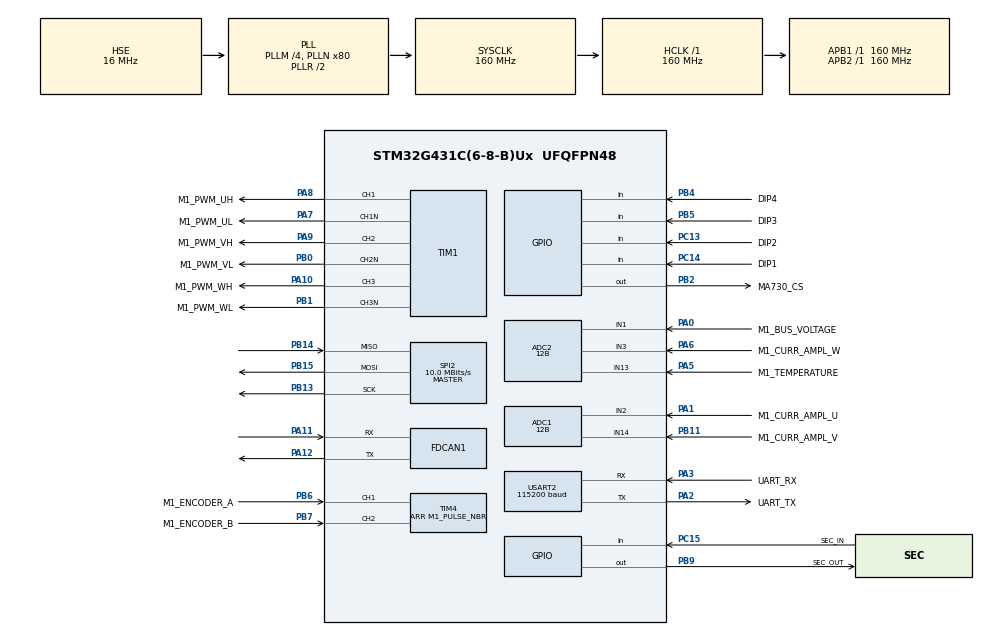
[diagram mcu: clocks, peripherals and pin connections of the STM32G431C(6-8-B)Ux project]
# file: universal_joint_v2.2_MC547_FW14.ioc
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ADC1.ClockPrescaler=ADC_CLOCK_ASYNC_DIV4
ADC1.ContinuousConvMode=DISABLE
ADC1.DMAContinuousRequests=DISABLE
ADC1.DataAlign=ADC_DATAALIGN_LEFT
ADC1.DiscontinuousConvMode=DISABLE
ADC1.EOCSelection=ADC_EOC_SINGLE_CONV
ADC1.EnableAnalogWatchDog1=false
ADC1.EnableAnalogWatchDog2=false
ADC1.EnableAnalogWatchDog3=false
ADC1.EnableInjectedConversion=ENABLE
ADC1.EnableRegularConversion=DISABLE
ADC1.ExternalTrigInjecConv=ADC_EXTERNALTRIGINJEC_T1_TRGO
ADC1.ExternalTrigInjecConvEdge=ADC_EXTERNALTRIGINJECCONV_EDGE_RISING
ADC1.InjNumberOfConversion=2
ADC1.InjectedChannel-1\#ChannelInjectedConversion=ADC_CHANNEL_2
ADC1.InjectedChannel-2\#ChannelInjectedConversion=ADC_CHANNEL_14
ADC1.InjectedConvMode=None
ADC1.InjectedOffset-1\#ChannelInjectedConversion=0
ADC1.InjectedOffset-2\#ChannelInjectedConversion=0
ADC1.InjectedOffsetNumber-1\#ChannelInjectedConversion=ADC_OFFSET_NONE
ADC1.InjectedOffsetNumber-2\#ChannelInjectedConversion=ADC_OFFSET_NONE
ADC1.InjectedRank-1\#ChannelInjectedConversion=1
ADC1.InjectedRank-2\#ChannelInjectedConversion=2
ADC1.InjectedSamplingTime-1\#ChannelInjectedConversion=ADC_SAMPLETIME_6CYCLES_5
ADC1.InjectedSamplingTime-2\#ChannelInjectedConversion=ADC_SAMPLETIME_6CYCLES_5
ADC1.LowPowerAutoWait=DISABLE
ADC1.Overrun=ADC_OVR_DATA_PRESERVED
ADC1.Resolution=ADC_RESOLUTION_12B
ADC1.ScanConvMode=ADC_SCAN_ENABLE
ADC1.master=1
ADC2.Channel-1\#ChannelRegularConversion=ADC_CHANNEL_1
ADC2.Channel-2\#ChannelRegularConversion=ADC_CHANNEL_13
ADC2.ClockPrescaler=ADC_CLOCK_ASYNC_DIV4
ADC2.ContinuousConvMode=DISABLE
ADC2.DMAContinuousRequests=DISABLE
ADC2.DataAlign=ADC_DATAALIGN_LEFT
ADC2.DiscontinuousConvMode=DISABLE
ADC2.EOCSelection=ADC_EOC_SINGLE_CONV
ADC2.EnableAnalogWatchDog1=false
ADC2.EnableAnalogWatchDog2=false
ADC2.EnableAnalogWatchDog3=false
ADC2.EnableInjectedConversion=ENABLE
ADC2.EnableRegularConversion=ENABLE
ADC2.ExternalTrigConv=ADC_SOFTWARE_START
ADC2.ExternalTrigConvEdge=ADC_EXTERNALTRIGCONVEDGE_NONE
ADC2.ExternalTrigInjecConv=ADC_EXTERNALTRIGINJEC_T1_TRGO
ADC2.ExternalTrigInjecConvEdge=ADC_EXTERNALTRIGINJECCONV_EDGE_RISING
ADC2.InjNumberOfConversion=2
ADC2.InjectedChannel-1\#ChannelInjectedConversion=ADC_CHANNEL_14
ADC2.InjectedChannel-2\#ChannelInjectedConversion=ADC_CHANNEL_3
ADC2.InjectedConvMode=None
ADC2.InjectedOffset-1\#ChannelInjectedConversion=0
ADC2.InjectedOffset-2\#ChannelInjectedConversion=0
ADC2.InjectedOffsetNumber-1\#ChannelInjectedConversion=ADC_OFFSET_NONE
ADC2.InjectedOffsetNumber-2\#ChannelInjectedConversion=ADC_OFFSET_NONE
ADC2.InjectedRank-1\#ChannelInjectedConversion=1
ADC2.InjectedRank-2\#ChannelInjectedConversion=2
ADC2.InjectedSamplingTime-1\#ChannelInjectedConversion=ADC_SAMPLETIME_6CYCLES_5
ADC2.InjectedSamplingTime-2\#ChannelInjectedConversion=ADC_SAMPLETIME_6CYCLES_5
ADC2.LowPowerAutoWait=DISABLE
ADC2.NbrOfConversion=2
ADC2.NbrOfConversionFlag=1
ADC2.Offset-1\#ChannelRegularConversion=0
ADC2.Offset-2\#ChannelRegularConversion=0
ADC2.OffsetNumber-1\#ChannelRegularConversion=ADC_OFFSET_NONE
ADC2.OffsetNumber-2\#ChannelRegularConversion=ADC_OFFSET_NONE
ADC2.Overrun=ADC_OVR_DATA_PRESERVED
ADC2.Rank-1\#ChannelRegularConversion=1
ADC2.Rank-2\#ChannelRegularConversion=2
ADC2.Resolution=ADC_RESOLUTION_12B
ADC2.SamplingTime-1\#ChannelRegularConversion=ADC_SAMPLETIME_47CYCLES_5
ADC2.SamplingTime-2\#ChannelRegularConversion=ADC_SAMPLETIME_47CYCLES_5
ADC2.ScanConvMode=ADC_SCAN_ENABLE
ADC2.master=1
ExtraMW=MotorControl
ExtraMW.MotorControl.Config=MotorControl
ExtraMW.MotorControl.Mode=MotorControl
ExtraMW.MotorControl.Root=MCSDK_v5.4.7/MotorControl
ExtraMW.MotorControl.Template=templates
FDCAN1.AutoRetransmission=ENABLE
FDCAN1.ClockDivider=FDCAN_CLOCK_DIV2
FDCAN1.DataSyncJumpWidth=3
FDCAN1.DataTimeSeg1=12
FDCAN1.DataTimeSeg2=3
FDCAN1.FrameFormat=FDCAN_FRAME_FD_BRS
FDCAN1.NominalPrescaler=5
FDCAN1.NominalSyncJumpWidth=3
FDCAN1.NominalTimeSeg1=12
FDCAN1.NominalTimeSeg2=3
FDCAN1.StdFiltersNbr=1
FDCAN1.TransmitPause=ENABLE
Mcu.Family=STM32G4
Mcu.Name=STM32G431C(6-8-B)Ux
Mcu.Package=UFQFPN48
MotorControl.ADC_1_PERIPH=ADC1
MotorControl.ADC_2_PERIPH=ADC2
MotorControl.ADC_AHBPERIPH=RCC_AHBPeriph_ADC12
MotorControl.ADC_CLOCK_WB_DIV=4
MotorControl.ADC_CLOCK_WB_FREQ=42.5
MotorControl.ADC_PERIPH=ADC1
MotorControl.ADC_REFERENCE_VOLTAGE=3.30
MotorControl.ALIGNMENT_ANGLE_DEG=90
MotorControl.ALIGNMENT_DURATION=700
MotorControl.AMPLIFICATION_GAIN=5.00
MotorControl.ANGC={0,0,0,0,0,0,0,0}
MotorControl.BEMF_CONSISTENCY_GAIN=64
MotorControl.BEMF_CONSISTENCY_TOL=64
MotorControl.BKIN1_FILTER=0
MotorControl.BKIN2_FILTER=0
MotorControl.BKIN2_MODE=NONE
MotorControl.BKIN_MODE=NONE
MotorControl.BOARD=CUSTOM
MotorControl.BRKIN2_GPIO_AF=GPIO_AF_12
MotorControl.BRKIN_GPIO_AF=GPIO_AF_2
MotorControl.BUS_VOLTAGE_READING=true
MotorControl.CCMRAM_ENABLED=false
MotorControl.CLOCK_FREQUENCY=CPU_CLK_170_MHZ
MotorControl.CLOCK_SOURCE=EXTERNAL
MotorControl.CONSTANT1_D=66796
MotorControl.CONSTANT1_Q=66796
MotorControl.CONSTANT2_QD=5301
MotorControl.CORD_BEMF_CONSISTENCY_GAIN=64
MotorControl.CORD_BEMF_CONSISTENCY_TOL=64
MotorControl.CORD_F1=16384
MotorControl.CORD_F2=16384
MotorControl.CORD_FIFO_DEPTH_01HZ=64
MotorControl.CORD_FIFO_DEPTH_DPP=64
MotorControl.CORD_GAIN1=-22503
MotorControl.CORD_GAIN2=11099
MotorControl.CORD_MAX_ACCEL_DPPP=3373
MotorControl.CORD_MEAS_ERRORS_BEFORE_FAULTS=3
MotorControl.CORD_VARIANCE_THRESHOLD=4
MotorControl.CPU_CLK_170_MHZ=true
MotorControl.CTRBDID=0
MotorControl.CUBE_MX_VER=6.3.0
MotorControl.CURRENT_READING_TOPOLOGY=THREE_SHUNT_INDEPENDENT_RESOURCES
MotorControl.CURR_SAMPLING_TIME=6
MotorControl.DAC_EMULATED=false
MotorControl.DAC_FUNCTIONALITY=false
MotorControl.DAC_TIMER_CH1_GPIO_PIN=LL_GPIO_PIN_0
MotorControl.DAC_TIMER_CH1_GPIO_PORT=GPIOA
MotorControl.DAC_TIMER_CH2_GPIO_PIN=LL_GPIO_PIN_0
MotorControl.DAC_TIMER_CH2_GPIO_PORT=GPIOA
MotorControl.DAC_TIMER_SELECTION=TIM3
MotorControl.DC_CURRENT_RS_MEAS=16.80
MotorControl.DEBUG_DAC_CH1=false
MotorControl.DEBUG_DAC_CH2=false
MotorControl.DEFAULT_CONTROL_MODE=STC_TORQUE_MODE
MotorControl.DEFAULT_DAC_CHANNEL_1=MC_PROTOCOL_REG_I_A
MotorControl.DEFAULT_DAC_CHANNEL_2=MC_PROTOCOL_REG_I_B
MotorControl.DEFAULT_DAC_MOTOR=0
MotorControl.DEFAULT_FLUX_COMPONENT=0
MotorControl.DEFAULT_TARGET_SPEED_RPM=1500
MotorControl.DEFAULT_TORQUE_COMPONENT=0
MotorControl.DISSIPATIVE_BRAKE_POLARITY=DOUT_ACTIVE_HIGH
MotorControl.DRIVES_NUMBER_SELECTION=SINGLEDRIVE
MotorControl.EMERGENCY2_STOP_GPIO_PIN=LL_GPIO_PIN_11
MotorControl.EMERGENCY2_STOP_GPIO_PORT=GPIOA
MotorControl.EMERGENCY_STOP_GPIO_PIN=LL_GPIO_PIN_11
MotorControl.EMERGENCY_STOP_GPIO_PORT=GPIOA
MotorControl.ENABLE_SL_ALGO_FROM_PHASE=3
MotorControl.ENCODER=true
MotorControl.ENCODER_AVAILABLE=true
MotorControl.ENCODER_PPR=3584
MotorControl.ENC_AVERAGING_FIFO_DEPTH=16
MotorControl.ENC_A_GPIO_PIN=LL_GPIO_PIN_6
MotorControl.ENC_A_GPIO_PORT=GPIOB
MotorControl.ENC_B_GPIO_PIN=LL_GPIO_PIN_7
MotorControl.ENC_B_GPIO_PORT=GPIOB
MotorControl.ENC_ICx_FILTER=128
MotorControl.ENC_INVERT_SPEED=false
MotorControl.ENC_MEAS_ERRORS_BEFORE_FAULTS=3
MotorControl.ENC_TIMER_REMAPPING=NO_REMAP_TIM4
MotorControl.ENC_TIMER_SELECTION=ENC_TIM4
MotorControl.ENC_USE_CH3=false
MotorControl.EXT_CLK_8_MHZ=true
MotorControl.EXT_CLOCK_FREQUENCY=EXT_CLK_8_MHZ
MotorControl.F1=16384
MotorControl.F2=16384
MotorControl.FEEDBACK_NET_FILTERING=false
MotorControl.FEED_FORWARD_CURRENT_REG_ENABLING=false
MotorControl.FINAL_I_ALIGNMENT=1936
MotorControl.FLUX_WEAKENING_ENABLING=false
MotorControl.FW_KIDIV=32768
MotorControl.FW_KI_GAIN=5000
MotorControl.FW_KPDIV=32768
MotorControl.FW_KP_GAIN=3000
MotorControl.FW_VOLTAGE_REF=985
MotorControl.GAIN1=-22503
MotorControl.GAIN2=11099
MotorControl.H1_GPIO_PIN=LL_GPIO_PIN_15
MotorControl.H1_GPIO_PORT=GPIOA
MotorControl.H2_GPIO_PIN=LL_GPIO_PIN_3
MotorControl.H2_GPIO_PORT=GPIOB
MotorControl.H3_GPIO_PIN=LL_GPIO_PIN_10
MotorControl.H3_GPIO_PORT=GPIOB
MotorControl.HALL_AVERAGING_FIFO_DEPTH=6
MotorControl.HALL_ICx_FILTER=255
MotorControl.HALL_MEAS_ERRORS_BEFORE_FAULTS=3
MotorControl.HALL_MTPA=false
MotorControl.HALL_PHASE_SHIFT=60
MotorControl.HALL_SENSORS_AVAILABLE=false
MotorControl.HALL_SENSORS_PLACEMENT=DEGREES_120
MotorControl.HALL_TIMER_REMAPPING=NO_REMAP_TIM2
MotorControl.HALL_TIMER_SELECTION=HALL_TIM2
MotorControl.HFI_AMPLITUDE=25
MotorControl.HFI_DC_0_COEFF=0.00146
MotorControl.HFI_DC_1_COEFF=0.002921
MotorControl.HFI_DC_2_COEFF=0.00146
MotorControl.HFI_DC_3_COEFF=1.889033
MotorControl.HFI_DC_4_COEFF=-0.894874
MotorControl.HFI_DEBUG_MODE=false
MotorControl.HFI_FREQUENCY=400
MotorControl.HFI_HIFRAMPLSCAN=25
MotorControl.HFI_HP_ID_0_COEFF=0.732023
MotorControl.HFI_HP_ID_1_COEFF=-1.464045
MotorControl.HFI_HP_ID_2_COEFF=0.732023
MotorControl.HFI_HP_ID_3_COEFF=1.390895
MotorControl.HFI_HP_ID_4_COEFF=-0.537195
MotorControl.HFI_IDH_DELAY=32400
MotorControl.HFI_LOCKFREQ=164
MotorControl.HFI_LP_ID_0_COEFF=0.104078
MotorControl.HFI_LP_ID_1_COEFF=0.208157
MotorControl.HFI_LP_ID_2_COEFF=0.104078
MotorControl.HFI_LP_ID_3_COEFF=0.903419
MotorControl.HFI_LP_ID_4_COEFF=-0.319732
MotorControl.HFI_MAXANGLEDIFF=3640
MotorControl.HFI_MINIMUM_SPEED_RPM=402
MotorControl.HFI_NOTCH_IQD_0_COEFF=0.87188
MotorControl.HFI_NOTCH_IQD_1_COEFF=-1.410732
MotorControl.HFI_NOTCH_IQD_2_COEFF=0.87188
MotorControl.HFI_NOTCH_IQD_3_COEFF=1.410732
MotorControl.HFI_NOTCH_IQD_4_COEFF=-0.743761
MotorControl.HFI_NSDETPOINTSSKIP=10
MotorControl.HFI_NSMAXDETPOINTS=20
MotorControl.HFI_NS_MIN_SAT_DIFF=0
MotorControl.HFI_PID_KIDIV=32768
MotorControl.HFI_PID_KI_DEFAULT=400
MotorControl.HFI_PID_KPDIV=16384
MotorControl.HFI_PID_KP_DEFAULT=800
MotorControl.HFI_PLL_KI_DEFAULT=0.00400
MotorControl.HFI_PLL_KP_DEFAULT=0.00060
MotorControl.HFI_RESTARTTIMESEC=0.1
MotorControl.HFI_RESTART_RPM_TH=(((HFI_STO_RPM_TH)+(STO_HFI_RPM_TH))/2)
MotorControl.HFI_REVERT_DIRECTION=true
MotorControl.HFI_SCANROTATIONSNO=3
MotorControl.HFI_SPD_BUFFER_DEPTH_01HZ=64
MotorControl.HFI_STEPANGLE=3640
MotorControl.HFI_STO_RPM_TH=OBS_MINIMUM_SPEED_RPM
MotorControl.HFI_WAITAFTERNS2=4
MotorControl.HFI_WAITBEFORESN=6
MotorControl.HFI_WAITSYNCH=20
MotorControl.HFI_WAITTRACK=20
MotorControl.HIGH_SIDE_BRAKE_STATE=false
MotorControl.HIGH_SIDE_IDLE_STATE=false
MotorControl.HW_COMPLEMENTED_LOW_SIDE=false
MotorControl.HW_DEAD_TIME_NS=100
MotorControl.HW_OV_CURRENT_PROT_BYPASS=false
MotorControl.ID_DEMAG=-16681
MotorControl.INRUSH_CURRLIMIT_AT_POWER_ON=true
MotorControl.INRUSH_CURRLIMIT_CHANGE_AFTER_MS=1000
MotorControl.INRUSH_CURRLIMIT_ENABLING=false
MotorControl.INRUSH_CURRLIMIT_GPIO_PIN=LL_GPIO_PIN_4
MotorControl.INRUSH_CURRLIMIT_GPIO_PORT=GPIOE
MotorControl.INRUSH_CURR_LIMITER_POLARITY=DOUT_ACTIVE_HIGH
MotorControl.INTERNAL_OVERCURRENTPROTECTION=false
MotorControl.INTERNAL_OVERVOLTAGEPROTECTION=false
MotorControl.IPs=CORDIC,NVIC,RCC,SYS,MotorControl,TIM1,ADC1,ADC2,TIM4,USART2
MotorControl.IQMAX=16681
MotorControl.LCD_JOYSTICK_FUNCTIONALITY=false
MotorControl.LCD_MODE=LCD_FULL
MotorControl.LDLQ_RATIO=1.000
MotorControl.LOW_SIDE_BRAKE_STATE=false
MotorControl.LOW_SIDE_IDLE_STATE=false
MotorControl.LOW_SIDE_SIGNALS_ENABLING=LS_PWM_TIMER
MotorControl.LS=0.000311
MotorControl.MAX_APPLICATION_SPEED=3125
MotorControl.MAX_MODULATION_85_PER_CENT=true
MotorControl.MAX_MODULATION_INDEX=MAX_MODULATION_85_PER_CENT
MotorControl.MCU=STM32G431CB
MotorControl.MCU_TYPE=STM32G431CB
MotorControl.MC_WORKBENCH_VERSION=5.4.7.21279
MotorControl.MEAS_ERRORS_BEFORE_FAULTS=3
MotorControl.MIN_APPLICATION_SPEED=0
MotorControl.MOTOR_MAX_SPEED_RPM=3125
MotorControl.MOTOR_TYPE=PMSM
MotorControl.MOTOR_VOLTAGE_CONSTANT=11.7
MotorControl.MTPA_ENABLING=false
MotorControl.NB_CONSECUTIVE_TESTS=2
MotorControl.NOMINAL_BUS_VOLTAGE_V=48
MotorControl.NOMINAL_CURRENT=16681
MotorControl.OBS_MEAS_ERRORS_BEFORE_FAULTS=3
MotorControl.OBS_MINIMUM_SPEED_RPM=580
MotorControl.OCPA_INVERTINGINPUT=COMPX_InvertingInput_VREF
MotorControl.OCPA_INVERTINGINPUT_GPIO_PIN=LL_GPIO_PIN_4
MotorControl.OCPA_INVERTINGINPUT_GPIO_PORT=GPIOA
MotorControl.OCPA_INVERTINGINPUT_MODE=INT_MODE
MotorControl.OCPA_NONINVERTINGINPUT=COMP1_NonInvertingInput_PA1
MotorControl.OCPA_NONINVERTINGINPUT_GPIO_PIN=LL_GPIO_PIN_1
MotorControl.OCPA_NONINVERTINGINPUT_GPIO_PORT=GPIOA
MotorControl.OCPA_OUTPUT=COMP_Output_TIM1BKIN2
MotorControl.OCPA_OUTPUTPOL=COMP_OutputPol_NonInverted
MotorControl.OCPA_OUTPUT_GPIO_AF=GPIO_AF_2
MotorControl.OCPA_OUTPUT_GPIO_PIN=LL_GPIO_PIN_0
MotorControl.OCPA_OUTPUT_GPIO_PORT=GPIOA
MotorControl.OCPA_OUTPUT_MODE=INT_MODE
MotorControl.OCPA_SELECTION=COMP1
MotorControl.OCPB_INVERTINGINPUT=COMPX_InvertingInput_VREF
MotorControl.OCPB_INVERTINGINPUT_GPIO_PIN=LL_GPIO_PIN_4
MotorControl.OCPB_INVERTINGINPUT_GPIO_PORT=GPIOA
MotorControl.OCPB_INVERTINGINPUT_MODE=INT_MODE
MotorControl.OCPB_NONINVERTINGINPUT=COMP2_NonInvertingInput_PA7
MotorControl.OCPB_NONINVERTINGINPUT_GPIO_PIN=LL_GPIO_PIN_7
MotorControl.OCPB_NONINVERTINGINPUT_GPIO_PORT=GPIOA
MotorControl.OCPB_OUTPUT=COMP_Output_TIM1BKIN2
MotorControl.OCPB_OUTPUTPOL=COMP_OutputPol_NonInverted
MotorControl.OCPB_OUTPUT_GPIO_AF=GPIO_AF_2
MotorControl.OCPB_OUTPUT_GPIO_PIN=LL_GPIO_PIN_2
MotorControl.OCPB_OUTPUT_GPIO_PORT=GPIOA
MotorControl.OCPB_OUTPUT_MODE=INT_MODE
MotorControl.OCPB_SELECTION=COMP2
MotorControl.OCPC_INVERTINGINPUT=COMPX_InvertingInput_VREF
MotorControl.OCPC_INVERTINGINPUT_GPIO_PIN=LL_GPIO_PIN_4
MotorControl.OCPC_INVERTINGINPUT_GPIO_PORT=GPIOA
MotorControl.OCPC_INVERTINGINPUT_MODE=INT_MODE
MotorControl.OCPC_NONINVERTINGINPUT=COMP3_NonInvertingInput_PD14
MotorControl.OCPC_NONINVERTINGINPUT_GPIO_PIN=LL_GPIO_PIN_14
MotorControl.OCPC_NONINVERTINGINPUT_GPIO_PORT=GPIOD
MotorControl.OCPC_OUTPUT=COMP_Output_TIM1BKIN2
MotorControl.OCPC_OUTPUTPOL=COMP_OutputPol_NonInverted
MotorControl.OCPC_OUTPUT_GPIO_AF=GPIO_AF_2
MotorControl.OCPC_OUTPUT_GPIO_PIN=LL_GPIO_PIN_8
MotorControl.OCPC_OUTPUT_GPIO_PORT=GPIOC
MotorControl.OCPC_OUTPUT_MODE=INT_MODE
MotorControl.OCPC_SELECTION=COMP3
MotorControl.OCPREF=23830
MotorControl.OCP_COMP_THRESHOLD=0.50
MotorControl.OCP_FILTER=COMP_Mode_HighSpeed
MotorControl.OCP_INVERTINGINPUT=COMPX_InvertingInput_VREF
MotorControl.OCP_INVERTINGINPUT_GPIO_PIN=LL_GPIO_PIN_4
MotorControl.OCP_INVERTINGINPUT_GPIO_PORT=GPIOA
MotorControl.OCP_INVERTINGINPUT_MODE=INT_MODE
MotorControl.OCP_NONINVERTINGINPUT=COMP2_NonInvertingInput_PA7
MotorControl.OCP_NONINVERTINGINPUT_GPIO_PIN=LL_GPIO_PIN_7
MotorControl.OCP_NONINVERTINGINPUT_GPIO_PORT=GPIOA
MotorControl.OCP_OUTPUT=COMP_Output_TIM1BKIN2
MotorControl.OCP_OUTPUTPOL=COMP_OutputPol_NonInverted
MotorControl.OCP_OUTPUT_GPIO_AF=GPIO_AF_2
MotorControl.OCP_OUTPUT_GPIO_PIN=LL_GPIO_PIN_2
MotorControl.OCP_OUTPUT_GPIO_PORT=GPIOA
MotorControl.OCP_OUTPUT_MODE=INT_MODE
MotorControl.OCP_SELECTION=COMP2
MotorControl.OFST={0,0,0,0,0,0,0,0}
MotorControl.ON_OVER_VOLTAGE=TURN_ON_LOW_SIDES
MotorControl.OPAMP1_INVERTINGINPUT=OPAMP1_InvertingInput_PGA
MotorControl.OPAMP1_INVERTINGINPUT_GPIO_PIN=LL_GPIO_PIN_3
MotorControl.OPAMP1_INVERTINGINPUT_GPIO_PORT=GPIOA
MotorControl.OPAMP1_INVERTINGINPUT_MODE=INT_MODE
MotorControl.OPAMP1_NONINVERTINGINPUT_PHA=OPAMP1_NonInvertingInput_PA1
MotorControl.OPAMP1_NONINVERTINGINPUT_PHA_GPIO_PIN=LL_GPIO_PIN_1
MotorControl.OPAMP1_NONINVERTINGINPUT_PHA_GPIO_PORT=GPIOA
MotorControl.OPAMP1_NONINVERTINGINPUT_PHB=OPAMP1_NonInvertingInput_PA7
MotorControl.OPAMP1_NONINVERTINGINPUT_PHB_GPIO_PIN=LL_GPIO_PIN_7
MotorControl.OPAMP1_NONINVERTINGINPUT_PHB_GPIO_PORT=GPIOA
MotorControl.OPAMP1_OUT_GPIO_PIN=LL_GPIO_PIN_2
MotorControl.OPAMP1_OUT_GPIO_PORT=GPIOA
MotorControl.OPAMP1_SELECTION=OPAMP1
MotorControl.OPAMP2_INVERTINGINPUT=OPAMP2_InvertingInput_PGA
MotorControl.OPAMP2_INVERTINGINPUT_GPIO_PIN=LL_GPIO_PIN_5
MotorControl.OPAMP2_INVERTINGINPUT_GPIO_PORT=GPIOC
MotorControl.OPAMP2_INVERTINGINPUT_MODE=INT_MODE
MotorControl.OPAMP2_NONINVERTINGINPUT_PHA=OPAMP2_NonInvertingInput_PB14
MotorControl.OPAMP2_NONINVERTINGINPUT_PHA_GPIO_PIN=LL_GPIO_PIN_14
MotorControl.OPAMP2_NONINVERTINGINPUT_PHA_GPIO_PORT=GPIOB
MotorControl.OPAMP2_NONINVERTINGINPUT_PHB=OPAMP2_NonInvertingInput_PA7
MotorControl.OPAMP2_NONINVERTINGINPUT_PHB_GPIO_PIN=LL_GPIO_PIN_7
MotorControl.OPAMP2_NONINVERTINGINPUT_PHB_GPIO_PORT=GPIOA
MotorControl.OPAMP2_NONINVERTINGINPUT_PHC=OPAMP2_NonInvertingInput_PB14
MotorControl.OPAMP2_NONINVERTINGINPUT_PHC_GPIO_PIN=LL_GPIO_PIN_14
MotorControl.OPAMP2_NONINVERTINGINPUT_PHC_GPIO_PORT=GPIOB
MotorControl.OPAMP2_OUT_GPIO_PIN=LL_GPIO_PIN_6
MotorControl.OPAMP2_OUT_GPIO_PORT=GPIOA
MotorControl.OPAMP2_SELECTION=OPAMP2
MotorControl.OPAMP3_INVERTINGINPUT=OPAMP1_InvertingInput_PGA
MotorControl.OPAMP3_INVERTINGINPUT_GPIO_PIN=LL_GPIO_PIN_0
MotorControl.OPAMP3_INVERTINGINPUT_GPIO_PORT=GPIOA
MotorControl.OPAMP3_INVERTINGINPUT_MODE=INT_MODE
MotorControl.OPAMP3_SELECTION=OPAMP1
MotorControl.OPAMP_INVERTINGINPUT=OPAMP1_InvertingInput_PGA
MotorControl.OPAMP_INVERTINGINPUT_GPIO_PIN=LL_GPIO_PIN_3
MotorControl.OPAMP_INVERTINGINPUT_GPIO_PORT=GPIOA
MotorControl.OPAMP_INVERTINGINPUT_MODE=INT_MODE
MotorControl.OPAMP_NONINVERTINGINPUT=OPAMP1_NonInvertingInput_PA7
MotorControl.OPAMP_NONINVERTINGINPUT_GPIO_PIN=LL_GPIO_PIN_7
MotorControl.OPAMP_NONINVERTINGINPUT_GPIO_PORT=GPIOA
MotorControl.OPAMP_OUT_GPIO_PIN=LL_GPIO_PIN_2
MotorControl.OPAMP_OUT_GPIO_PORT=GPIOA
MotorControl.OPAMP_PGACONNECT=OPAMP_PGAConnect_No
MotorControl.OPAMP_PGAGAIN=OPAMP_OPAMP_PGAGain_2
MotorControl.OPAMP_SELECTION=OPAMP1
MotorControl.OPAMP_TYPE_GAIN=INTERNAL
MotorControl.OPEN_LOOP_FOC=false
MotorControl.OPEN_LOOP_K=44
MotorControl.OPEN_LOOP_OFF=4400
MotorControl.OPEN_LOOP_SPEED_RAMP_DURATION_MS=1000
MotorControl.OPEN_LOOP_SPEED_RPM=100
MotorControl.OPEN_LOOP_VF=false
MotorControl.OPEN_LOOP_VOLTAGE_d=6000
MotorControl.OVERCURR_FEEDBACK_POLARITY=EMSTOP_ACTIVE_LOW
MotorControl.OVERCURR_PROTECTION_HW_DISABLING=DOUT_ACTIVE_HIGH
MotorControl.OVPREF=23830
MotorControl.OVP_FILTER=COMP_Mode_HighSpeed
MotorControl.OVP_INVERTINGINPUT=COMPX_InvertingInput_VREF
MotorControl.OVP_INVERTINGINPUT_GPIO_PIN=LL_GPIO_PIN_4
MotorControl.OVP_INVERTINGINPUT_GPIO_PORT=GPIOA
MotorControl.OVP_INVERTINGINPUT_MODE=INT_MODE
MotorControl.OVP_NONINVERTINGINPUT=COMP7_NonInvertingInput_PA0
MotorControl.OVP_NONINVERTINGINPUT_GPIO_PIN=LL_GPIO_PIN_0
MotorControl.OVP_NONINVERTINGINPUT_GPIO_PORT=GPIOA
MotorControl.OVP_OUTPUT=COMP_Output_TIM1BKIN
MotorControl.OVP_OUTPUTPOL=COMP_OutputPol_NonInverted
MotorControl.OVP_OUTPUT_GPIO_AF=GPIO_AF_2
MotorControl.OVP_OUTPUT_GPIO_PIN=LL_GPIO_PIN_2
MotorControl.OVP_OUTPUT_GPIO_PORT=GPIOC
MotorControl.OVP_OUTPUT_MODE=INT_MODE
MotorControl.OVP_SELECTION=COMP7
MotorControl.OV_CURR_BYPASS_GPIO_PIN=LL_GPIO_PIN_5
MotorControl.OV_CURR_BYPASS_GPIO_PORT=GPIOE
MotorControl.OV_TEMPERATURE_HYSTERESIS_C=10
MotorControl.OV_TEMPERATURE_PROT_ENABLING=true
MotorControl.OV_TEMPERATURE_THRESHOLD_C=80
MotorControl.OV_VOLTAGE_PROT_ENABLING=true
MotorControl.OV_VOLTAGE_THRESHOLD_V=56
MotorControl.PHASE1_DURATION=0
MotorControl.PHASE1_FINAL_CURRENT=0
MotorControl.PHASE1_FINAL_SPEED_RPM=0
MotorControl.PHASE2_DURATION=700
MotorControl.PHASE2_FINAL_CURRENT=595
MotorControl.PHASE2_FINAL_SPEED_RPM=0
MotorControl.PHASE3_DURATION=350
MotorControl.PHASE3_FINAL_CURRENT=695
MotorControl.PHASE3_FINAL_SPEED_RPM=630
MotorControl.PHASE4_DURATION=1150
MotorControl.PHASE4_FINAL_CURRENT=695
MotorControl.PHASE4_FINAL_SPEED_RPM=2700
MotorControl.PHASE5_DURATION=0
MotorControl.PHASE5_FINAL_CURRENT=695
MotorControl.PHASE5_FINAL_SPEED_RPM=2700
MotorControl.PHASE_CURRENTS_ADC=ADC1_2
MotorControl.PHASE_CURRENTS_CHANNEL=ADC_CHANNEL_9
MotorControl.PHASE_CURRENTS_GPIO_PIN=LL_GPIO_PIN_0
MotorControl.PHASE_CURRENTS_GPIO_PORT=GPIOA
MotorControl.PHASE_UH_GPIO_AF=GPIO_AF_6
MotorControl.PHASE_UH_GPIO_PIN=LL_GPIO_PIN_8
MotorControl.PHASE_UH_GPIO_PORT=GPIOA
MotorControl.PHASE_UH_POLARITY=H_ACTIVE_HIGH
MotorControl.PHASE_UL_GPIO_AF=GPIO_AF_6
MotorControl.PHASE_UL_GPIO_PIN=LL_GPIO_PIN_7
MotorControl.PHASE_UL_GPIO_PORT=GPIOA
MotorControl.PHASE_UL_POLARITY=L_ACTIVE_HIGH
MotorControl.PHASE_U_CURR_ADC=ADC1_2
MotorControl.PHASE_U_CURR_CHANNEL=ADC_CHANNEL_2
MotorControl.PHASE_U_GPIO_PIN=LL_GPIO_PIN_1
MotorControl.PHASE_U_GPIO_PORT=GPIOA
MotorControl.PHASE_VH_GPIO_AF=GPIO_AF_6
MotorControl.PHASE_VH_GPIO_PIN=LL_GPIO_PIN_9
MotorControl.PHASE_VH_GPIO_PORT=GPIOA
MotorControl.PHASE_VH_POLARITY=H_ACTIVE_HIGH
MotorControl.PHASE_VL_GPIO_AF=GPIO_AF_6
MotorControl.PHASE_VL_GPIO_PIN=LL_GPIO_PIN_0
MotorControl.PHASE_VL_GPIO_PORT=GPIOB
MotorControl.PHASE_VL_POLARITY=L_ACTIVE_HIGH
MotorControl.PHASE_V_CURR_ADC=ADC1_2
MotorControl.PHASE_V_CURR_CHANNEL=ADC_CHANNEL_14
MotorControl.PHASE_V_GPIO_PIN=LL_GPIO_PIN_11
MotorControl.PHASE_V_GPIO_PORT=GPIOB
MotorControl.PHASE_WH_GPIO_AF=GPIO_AF_6
MotorControl.PHASE_WH_GPIO_PIN=LL_GPIO_PIN_10
MotorControl.PHASE_WH_GPIO_PORT=GPIOA
MotorControl.PHASE_WH_POLARITY=H_ACTIVE_HIGH
MotorControl.PHASE_WL_GPIO_AF=GPIO_AF_4
MotorControl.PHASE_WL_GPIO_PIN=LL_GPIO_PIN_1
MotorControl.PHASE_WL_GPIO_PORT=GPIOB
MotorControl.PHASE_WL_POLARITY=L_ACTIVE_HIGH
MotorControl.PHASE_W_CURR_ADC=ADC2
MotorControl.PHASE_W_CURR_CHANNEL=ADC_CHANNEL_3
MotorControl.PHASE_W_GPIO_PIN=LL_GPIO_PIN_6
MotorControl.PHASE_W_GPIO_PORT=GPIOA
MotorControl.PID_FLUX_KD_DEFAULT=100
MotorControl.PID_FLUX_KI_DEFAULT=591
MotorControl.PID_FLUX_KP_DEFAULT=3503
MotorControl.PID_SPEED_KD_DEFAULT=0
MotorControl.PID_SPEED_KI_DEFAULT=848
MotorControl.PID_SPEED_KP_DEFAULT=2214
MotorControl.PID_TORQUE_KD_DEFAULT=100
MotorControl.PID_TORQUE_KI_DEFAULT=591
MotorControl.PID_TORQUE_KP_DEFAULT=3503
MotorControl.PLL_KI_GAIN=1030
MotorControl.PLL_KP_GAIN=5819
MotorControl.POLE_PAIR_NUM=14
MotorControl.POSITION_CTRL_ENABLING=false
MotorControl.PWBDID=0
MotorControl.PWM_FREQUENCY=20000
MotorControl.PWM_TIMER_REMAPPING=PWM_NO_REMAP
MotorControl.PWM_TIMER_SELECTION=PWM_TIM1
MotorControl.REGCONVADC=ADC1
MotorControl.REGULATION_EXECUTION_RATE=5
MotorControl.RS=0.21
MotorControl.RSHUNT=0.01000
MotorControl.RTOS=NONE
MotorControl.R_BRAKE_GPIO_PIN=LL_GPIO_PIN_5
MotorControl.R_BRAKE_GPIO_PORT=GPIOE
MotorControl.R_BRAKE_SWITCH_OFF_THRES_V=45
MotorControl.SEGDIV=0
MotorControl.SERIAL_COMMUNICATION=true
MotorControl.SERIAL_COM_CHANNEL1=MC_PROTOCOL_REG_I_A
MotorControl.SERIAL_COM_CHANNEL2=MC_PROTOCOL_REG_I_A
MotorControl.SERIAL_COM_MODE=COM_BIDIRECTIONAL
MotorControl.SERIAL_COM_MOTOR=0
MotorControl.SHARED_SIGNAL_ENABLE=false
MotorControl.SINGLEDRIVE=true
MotorControl.SPD_DIFFERENTIAL_TERM_ENABLING=false
MotorControl.SPEED_BAND_LOWER_LIMIT=15
MotorControl.SPEED_BAND_UPPER_LIMIT=17
MotorControl.SPEED_LOOP_FREQUENCY_HZ=1000
MotorControl.SPEED_SENSOR_SELECTION=ENCODER
MotorControl.SP_KDDIV=16
MotorControl.SP_KIDIV=16384
MotorControl.SP_KPDIV=128
MotorControl.STARTING_ANGLE_DEG=90
MotorControl.START_STOP_BTN=true
MotorControl.START_STOP_GPIO_PIN=LL_GPIO_PIN_6
MotorControl.START_STOP_GPIO_PORT=GPIOE
MotorControl.START_STOP_POLARITY=DIN_ACTIVE_LOW
MotorControl.START_STOP_POLARITY_EDGE=GPIO_NOPULL
MotorControl.STM32G431CB=true
MotorControl.STO_FIFO_DEPTH_01HZ=64
MotorControl.STO_FIFO_DEPTH_DPP=64
MotorControl.STO_HFI_RPM_TH=460
MotorControl.SW_DEADTIME_NS=1600
MotorControl.SW_OV_CURRENT_PROT_ENABLING=false
MotorControl.T0_C=25
MotorControl.TEMPERATURE_READING=true
MotorControl.TEMP_ADC_SAMPLING_TIME=47
MotorControl.TEMP_FDBK_ADC=ADC2
MotorControl.TEMP_FDBK_CHANNEL=ADC_CHANNEL_13
MotorControl.TEMP_FDBK_GPIO_PIN=LL_GPIO_PIN_5
MotorControl.TEMP_FDBK_GPIO_PORT=GPIOA
MotorControl.TFDIFFERENTIAL_TERM_ENABLING=false
MotorControl.TF_KDDIV=8192
MotorControl.TF_KIDIV=16384
MotorControl.TF_KPDIV=16384
MotorControl.THREE_SHUNT_INDEPENDENT_RESOURCES=true
MotorControl.TNOISE_NS=2550
MotorControl.TRANSITION_DURATION=25
MotorControl.TRISE_NS=2550
MotorControl.T_MAX=80
MotorControl.UD_VOLTAGE_THRESHOLD_V=20
MotorControl.USART_REMAPPING=NO_REMAP_USART2
MotorControl.USART_RX_GPIO_PIN=LL_GPIO_PIN_3
MotorControl.USART_RX_GPIO_PORT=GPIOA
MotorControl.USART_SELECTION=USE_USART2
MotorControl.USART_SPEED=115200
MotorControl.USART_TX_GPIO_PIN=LL_GPIO_PIN_2
MotorControl.USART_TX_GPIO_PORT=GPIOA
MotorControl.USE_3OPAMPS=false
MotorControl.USE_INTERNAL_OPAMP=false
MotorControl.UV_VOLTAGE_PROT_ENABLING=true
MotorControl.V0_V=1.647
MotorControl.VARIANCE_THRESHOLD=0.1
MotorControl.VBUS_ADC=ADC1
MotorControl.VBUS_ADC_SAMPLING_TIME=47
MotorControl.VBUS_CHANNEL=ADC_CHANNEL_1
MotorControl.VBUS_GPIO_PIN=LL_GPIO_PIN_0
MotorControl.VBUS_GPIO_PORT=GPIOA
MotorControl.VBUS_PARTITIONING_FACTOR=0.0522
MotorControl.WB_to_Mx_template_version=21-02-18
MotorControl.WB_to_Mx_version=1.4.0
MotorControl.dV_dT=0.005
NVIC.ADC1_2_IRQn=true\:2\:0\:true\:true\:false\:3\:true\:true
NVIC.FDCAN1_IT0_IRQn=true\:0\:0\:false\:false\:true\:true\:true
NVIC.PriorityGroup=NVIC_PRIORITYGROUP_3
NVIC.SPI2_IRQn=true\:0\:0\:false\:false\:true\:true\:true
NVIC.TIM1_BRK_TIM15_IRQn=true\:4\:1\:true\:true\:false\:1\:true\:true
NVIC.TIM1_UP_TIM16_IRQn=true\:0\:0\:false\:true\:false\:2\:true\:true
NVIC.TIM4_IRQn=true\:3\:0\:false\:true\:false\:4\:true\:true
NVIC.TIM6_DAC_IRQn=true\:0\:0\:true\:false\:true\:true\:true
NVIC.USART2_IRQn=true\:3\:1\:true\:true\:false\:5\:true\:true
PA0.GPIO_Label=M1_BUS_VOLTAGE
PA0.Mode=IN1-Single-Ended
PA0.Signal=ADC2_IN1
PA1.GPIO_Label=M1_CURR_AMPL_U
PA1.Mode=IN2-Single-Ended
PA1.Signal=ADC1_IN2
PA10.GPIO_Label=M1_PWM_WH
PA10.GPIO_PuPd=GPIO_PULLDOWN
PA10.GPIO_Speed=GPIO_SPEED_FREQ_HIGH
PA10.Signal=S_TIM1_CH3
PA11.Mode=FDCAN_Activate
PA11.Signal=FDCAN1_RX
PA12.Mode=FDCAN_Activate
PA12.Signal=FDCAN1_TX
PA13.GPIO_Label=TMS
PA13.Mode=Serial_Wire
PA13.Signal=SYS_JTMS-SWDIO
PA14.GPIO_Label=TCK
PA14.Mode=Serial_Wire
PA14.Signal=SYS_JTCK-SWCLK
PA2.GPIO_Label=UART_TX
PA2.GPIO_Mode=GPIO_MODE_AF_PP
PA2.GPIO_PuPd=GPIO_NOPULL
PA2.GPIO_Speed=GPIO_SPEED_FREQ_LOW
PA2.Mode=Asynchronous
PA2.Signal=USART2_TX
PA3.GPIO_Label=UART_RX
PA3.GPIO_Mode=GPIO_MODE_AF_PP
PA3.GPIO_PuPd=GPIO_NOPULL
PA3.GPIO_Speed=GPIO_SPEED_FREQ_LOW
PA3.Mode=Asynchronous
PA3.Signal=USART2_RX
PA5.GPIO_Label=M1_TEMPERATURE
PA5.Mode=IN13-Single-Ended
PA5.Signal=ADC2_IN13
PA6.GPIO_Label=M1_CURR_AMPL_W
PA6.Mode=IN3-Single-Ended
PA6.Signal=ADC2_IN3
PA7.GPIO_Label=M1_PWM_UL
PA7.GPIO_PuPd=GPIO_PULLDOWN
PA7.GPIO_Speed=GPIO_SPEED_FREQ_HIGH
PA7.Mode=PWM Generation1 CH1 CH1N
PA7.Signal=TIM1_CH1N
PA8.GPIO_Label=M1_PWM_UH
PA8.GPIO_PuPd=GPIO_PULLDOWN
PA8.GPIO_Speed=GPIO_SPEED_FREQ_HIGH
PA8.Signal=S_TIM1_CH1
PA9.GPIO_Label=M1_PWM_VH
PA9.GPIO_PuPd=GPIO_PULLDOWN
PA9.GPIO_Speed=GPIO_SPEED_FREQ_HIGH
PA9.Signal=S_TIM1_CH2
PB0.GPIO_Label=M1_PWM_VL
PB0.GPIO_PuPd=GPIO_PULLDOWN
PB0.GPIO_Speed=GPIO_SPEED_FREQ_HIGH
PB0.Mode=PWM Generation2 CH2 CH2N
PB0.Signal=TIM1_CH2N
PB1.GPIO_Label=M1_PWM_WL
PB1.GPIO_PuPd=GPIO_PULLDOWN
PB1.GPIO_Speed=GPIO_SPEED_FREQ_HIGH
PB1.Mode=PWM Generation3 CH3 CH3N
PB1.Signal=TIM1_CH3N
PB11.GPIO_Label=M1_CURR_AMPL_V
PB11.Signal=SharedAnalog_PB11
PB13.Mode=Full_Duplex_Master
PB13.Signal=SPI2_SCK
PB14.Mode=Full_Duplex_Master
PB14.Signal=SPI2_MISO
PB15.Mode=Full_Duplex_Master
PB15.Signal=SPI2_MOSI
PB2.GPIO_Label=MA730_CS
PB2.Signal=GPIO_Output
PB4.GPIO_Label=DIP4
PB4.Signal=GPIO_Input
PB5.GPIO_Label=DIP3
PB5.Signal=GPIO_Input
PB6.GPIO_Label=M1_ENCODER_A
PB6.Signal=S_TIM4_CH1
PB7.GPIO_Label=M1_ENCODER_B
PB7.Signal=S_TIM4_CH2
PB9.GPIO_Label=SEC_OUT
PB9.Signal=GPIO_Output
PC13.GPIO_Label=DIP2
PC13.Signal=GPIO_Input
PC14-OSC32_IN.GPIO_Label=DIP1
PC14-OSC32_IN.Signal=GPIO_Input
PC15-OSC32_OUT.GPIO_Label=SEC_IN
PC15-OSC32_OUT.Signal=GPIO_Input
PF0-OSC_IN.Mode=HSE-External-Oscillator
PF0-OSC_IN.Signal=RCC_OSC_IN
PF1-OSC_OUT.Mode=HSE-External-Oscillator
PF1-OSC_OUT.Signal=RCC_OSC_OUT
ProjectManager.HeapSize=0x200
ProjectManager.StackSize=0x400
ProjectManager.TargetToolchain=STM32CubeIDE
RCC.ADC12CLockSelection=RCC_ADC12CLKSOURCE_PLL
RCC.ADC12Freq_Value=40000000
RCC.AHBFreq_Value=160000000
RCC.APB1Freq_Value=160000000
RCC.APB1TimFreq_Value=160000000
RCC.APB2Freq_Value=160000000
RCC.APB2TimFreq_Value=160000000
RCC.CortexFreq_Value=160000000
RCC.EXTERNAL_CLOCK_VALUE=12288000
RCC.HCLKFreq_Value=160000000
RCC.HSE_VALUE=16000000
RCC.HSI48_VALUE=48000000
RCC.HSI_VALUE=16000000
RCC.LSE_VALUE=32768
RCC.PLLM=RCC_PLLM_DIV4
RCC.PLLN=80
RCC.PLLP=RCC_PLLP_DIV8
RCC.PLLSourceVirtual=RCC_PLLSOURCE_HSE
RCC.SYSCLKFreq_VALUE=160000000
RCC.SYSCLKSource=RCC_SYSCLKSOURCE_PLLCLK
RCC.USBFreq_Value=160000000
RCC.VCOOutputFreq_Value=320000000
SH.S_TIM1_CH1.0=TIM1_CH1,PWM Generation1 CH1 CH1N
SH.S_TIM1_CH2.0=TIM1_CH2,PWM Generation2 CH2 CH2N
SH.S_TIM1_CH3.0=TIM1_CH3,PWM Generation3 CH3 CH3N
SH.S_TIM4_CH1.0=TIM4_CH1,Encoder_Interface
SH.S_TIM4_CH2.0=TIM4_CH2,Encoder_Interface
SH.SharedAnalog_PB11.0=ADC1_IN14,IN14-Single-Ended
SH.SharedAnalog_PB11.1=ADC2_IN14,IN14-Single-Ended
SPI2.BaudRatePrescaler=SPI_BAUDRATEPRESCALER_16
SPI2.CLKPhase=SPI_PHASE_1EDGE
SPI2.CLKPolarity=SPI_POLARITY_LOW
SPI2.CalculateBaudRate=10.0 MBits/s
SPI2.DataSize=SPI_DATASIZE_16BIT
SPI2.Direction=SPI_DIRECTION_2LINES
SPI2.Mode=SPI_MODE_MASTER
SPI2.VirtualType=VM_MASTER
TIM1.AutoReloadPreload=TIM_AUTORELOAD_PRELOAD_DISABLE
TIM1.AutomaticOutput=TIM_AUTOMATICOUTPUT_DISABLE
TIM1.Break2Filter=0
TIM1.Break2Polarity=TIM_BREAK2POLARITY_HIGH
TIM1.Break2State=TIM_BREAK2_DISABLE
TIM1.BreakFilter=0
TIM1.BreakPolarity=TIM_BREAKPOLARITY_LOW
TIM1.BreakState=TIM_BREAK_DISABLE
TIM1.Channel=TIM_CHANNEL_4
TIM1.Channel-PWM\ Generation1\ CH1\ CH1N=TIM_CHANNEL_1
TIM1.Channel-PWM\ Generation2\ CH2\ CH2N=TIM_CHANNEL_2
TIM1.Channel-PWM\ Generation3\ CH3\ CH3N=TIM_CHANNEL_3
TIM1.Channel-PWM\ Generation4\ No\ Output=TIM_CHANNEL_4
TIM1.ClearInputSource=TIM_CLEARINPUTSOURCE_NONE
TIM1.ClockDivision=TIM_CLOCKDIVISION_DIV2
TIM1.CounterMode=TIM_COUNTERMODE_CENTERALIGNED1
TIM1.DeadTime=((DEAD_TIME_COUNTS) / 2)
TIM1.LockLevel=TIM_LOCKLEVEL_1
TIM1.OCFastMode_PWM=TIM_OCFAST_DISABLE
TIM1.OCIdleState_1=TIM_OCIDLESTATE_RESET
TIM1.OCIdleState_2=TIM_OCIDLESTATE_RESET
TIM1.OCIdleState_3=TIM_OCIDLESTATE_RESET
TIM1.OCIdleState_4=TIM_OCIDLESTATE_RESET
TIM1.OCIdleState_5=TIM_OCIDLESTATE_RESET
TIM1.OCIdleState_6=TIM_OCIDLESTATE_RESET
TIM1.OCMode_PWM-PWM\ Generation1\ CH1\ CH1N=TIM_OCMODE_PWM1
TIM1.OCMode_PWM-PWM\ Generation2\ CH2\ CH2N=TIM_OCMODE_PWM1
TIM1.OCMode_PWM-PWM\ Generation3\ CH3\ CH3N=TIM_OCMODE_PWM1
TIM1.OCMode_PWM-PWM\ Generation4\ No\ Output=TIM_OCMODE_PWM2
TIM1.OCNIdleState_1=TIM_OCNIDLESTATE_RESET
TIM1.OCNIdleState_2=TIM_OCNIDLESTATE_RESET
TIM1.OCNIdleState_3=TIM_OCNIDLESTATE_RESET
TIM1.OCNPolarity_1=TIM_OCNPOLARITY_HIGH
TIM1.OCNPolarity_2=TIM_OCNPOLARITY_HIGH
TIM1.OCNPolarity_3=TIM_OCNPOLARITY_HIGH
TIM1.OCPolarity_1=TIM_OCPOLARITY_HIGH
TIM1.OCPolarity_2=TIM_OCPOLARITY_HIGH
TIM1.OCPolarity_3=TIM_OCPOLARITY_HIGH
TIM1.OCPolarity_4=TIM_OCPOLARITY_HIGH
TIM1.OCPolarity_5=TIM_OCPOLARITY_HIGH
TIM1.OCPolarity_6=TIM_OCPOLARITY_HIGH
TIM1.OffStateIDLEMode=TIM_OSSI_ENABLE
TIM1.OffStateRunMode=TIM_OSSR_ENABLE
TIM1.Period=((PWM_PERIOD_CYCLES) / 2)
TIM1.PeriodNoDither=((PWM_PERIOD_CYCLES) / 2)
TIM1.Prescaler=((TIM_CLOCK_DIVIDER) - 1)
TIM1.Pulse-PWM\ Generation1\ CH1=((PWM_PERIOD_CYCLES) / 4)
TIM1.Pulse-PWM\ Generation2\ CH2=((PWM_PERIOD_CYCLES) / 4)
TIM1.Pulse-PWM\ Generation3\ CH3=((PWM_PERIOD_CYCLES) / 4)
TIM1.Pulse-PWM\ Generation4\ No\ Output=(((PWM_PERIOD_CYCLES) / 2) - (HTMIN))
TIM1.Pulse-PWM\ Generation5\ No\ Output=(((PWM_PERIOD_CYCLES) / 2) + 1)
TIM1.Pulse-PWM\ Generation6\ No\ Output=(((PWM_PERIOD_CYCLES) / 2) + 1)
TIM1.RepetitionCounter=(REP_COUNTER)
TIM1.SourceBRK2DigInput=TIM_BREAKINPUTSOURCE_DISABLE
TIM1.TIM_MasterOutputTrigger=TIM_TRGO_OC4REF
TIM1.TIM_MasterOutputTrigger2=TIM_TRGO2_RESET
TIM1.TIM_MasterSlaveMode=TIM_MASTERSLAVEMODE_DISABLE
TIM1.TIM_SlaveMode=TIM_SLAVEMODE_TRIGGER
TIM4.EncoderMode=TIM_ENCODERMODE_TI12
TIM4.IC1Filter=M1_ENC_IC_FILTER
TIM4.IC1Polarity=TIM_ICPOLARITY_RISING
TIM4.IC2Filter=M1_ENC_IC_FILTER
TIM4.IC2Polarity=TIM_ICPOLARITY_RISING
TIM4.Period=M1_PULSE_NBR
TIM6.PeriodNoDither=15999
USART2.BaudRate=115200
USART2.VirtualMode-Asynchronous=VM_ASYNC
USART2.WordLength=WORDLENGTH_8B
VP_CORDIC_VS_CORDIC.Mode=CORDIC_Activate
VP_MotorControl_MC_ENABLED.Mode=Enabled
VP_SYS_VS_DBSignals.Mode=DisableDeadBatterySignals
VP_TIM1_VS_ClockSourceITR.Mode=TriggerSource_ITR1
VP_TIM1_VS_ControllerModeTrigger.Mode=Trigger Mode
VP_TIM1_VS_no_output4.Mode=PWM Generation4 No Output
VP_TIM6_VS_ClockSourceINT.Mode=Enable_Timer
board=custom

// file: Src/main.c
/* USER CODE BEGIN Header */
/**
  ******************************************************************************
  * @file           : main.c
  * @brief          : Main program body
  ******************************************************************************
  * @attention
  *
  * <h2><center>&copy; Copyright (c) 2021 STMicroelectronics.
  * All rights reserved.</center></h2>
  *
  * This software component is licensed by ST under Ultimate Liberty license
  * SLA0044, the "License"; You may not use this file except in compliance with
  * the License. You may obtain a copy of the License at:
  *                             www.st.com/SLA0044
  *
  ******************************************************************************
  */

/* USER CODE END Header */
#include "main.h"

/* USER CODE BEGIN Includes */
#include <math.h>
/* USER CODE END Includes */

/* USER CODE BEGIN PTD */
// ERRORRS
#define  JOINT_NO_ERROR  						(uint8_t)(0x00u)      /**< @brief No error.*/
#define  JOINT_POSITION_ENCODER_FAILED  		(uint8_t)(0x01u)
#define  JOINT_MC_FAILED  						(uint8_t)(0x02u)
#define  JOINT_JOINT_SPEED_TO_HIGH  			(uint8_t)(0x04u)
#define  JOINT_NOT_CALIBRATED_@  					(uint8_t)(0x08u)

// WARNINGS
#define  JOINT_NO_WARNING  						(uint8_t)(0x00u)      /**< @brief No error.*/
#define  JOINT_POSITION_NOT_ACCURATE			(uint8_t)(0x01u)
#define  JOINT_OUTSIDE_WORKING_AREA				(uint8_t)(0x02u)
#define  JOINT_MA730_NOT_PROPER_MAGNETOC_FIELD	(uint8_t)(0x02u)

#define CURRENT_TORQUE_DATA_SIZE (uint8_t) 50

#define BUFF_SIZE 32

//#if defined CALIBRATION
typedef enum Calibration_State {
	CALIBRATION_NOT_FINISHED = 0, /**< @brief Starting uC.*/
	CALIBRATION_TABLE_NOT_FILLED = 1, // No difference between hi and low value of the sector
	SECTORS_NARROW = 2, // No difference between hi and low value of the sector
	SECTORS_INTERCECTION = 3, // intersection of the sectors > 0
	SECTORS_NOT_SEPARETED = 3, // intersection of the sectors > 0
	CALIBRATION_TABLE_CONTAINS_ZEROES = 4,
	MISSED_CENTER_POSITION = 100,
	FLASH_DOESNT_WRITE_PROPERLY = 100,
	CALIBRATION_OK = 255
} Calibration_State_t;

typedef enum FSM_State {
	FSM_START = 0, /**< @brief Starting uC.*/
	FSM_INIT = 1,
	FSM_READY_TO_OPERATE = 2,
	FSM_OPERATION_ENABLE = 3, /**< @brief Enable power.*/

	FSM_CALIBRATION_PHASE_1 = 101,
	FSM_CALIBRATION_PHASE_2 = 102,
	FSM_CALIBRATION_PHASE_3 = 103,
	FSM_CALIBRATION_PHASE_4 = 104,
	FSM_CALIBRATION_PHASE_5 = 105,
	FSM_CALIBRATION_PHASE_6 = 106,

	FSM_TRANSITION_START_TO_INIT = 10,
	FSM_TRANSITION_INIT_TO_READY_TO_OPERATE = 11,
	FSM_TRANSITION_READY_TO_OPERATE_TO_OPERATION_ENABLE = 12,
	FSM_TRANSITION_OPERATION_ENABLE_TO_READY_TO_OPERATE = 13,
	FSM_TRANSITION_FAULT_REACTION_ACTIVE_TO_FAULT = 14,
	FSM_TRANSITION_FAULT_TO_INIT = 15,

	FSM_TRANSITION_INIT_TO_CALIBRATION_PHASE_1 = 110,
	FSM_TRANSITION_CALIBRATION_PHASE_1_TO_CALIBRATION_PHASE_2 = 111,
	FSM_TRANSITION_CALIBRATION_PHASE_2_TO_CALIBRATION_PHASE_3 = 112,
	FSM_TRANSITION_CALIBRATION_PHASE_3_TO_CALIBRATION_PHASE_4 = 113,
	FSM_TRANSITION_CALIBRATION_PHASE_4_TO_CALIBRATION_PHASE_5 = 114,
	FSM_TRANSITION_CALIBRATION_PHASE_5_TO_CALIBRATION_PHASE_6 = 115,
	FSM_TRANSITION_CALIBRATION_PHASE_6_TO_INIT = 111,

	FSM_FAULT_REACTION_ACTIVE = 254,
	FSM_FAULT = 255
} FSM_State_t;

//#endif

typedef enum Joint_Position_State {
	POSITION_UNDER_WORKING_AREA = -1,
	POSITION_IN_WORKING_AREA = 0, /**< @brief Starting uC.*/
	POSITION_OVER_WORKING_AREA = 1
} Joint_Position_State_t;

typedef enum Encoder_Position_State {
	POSITION_UNKNOWN = 0, /**< @brief Starting uC.*/
	POSITION_APROXIMATED = 1,
	POSITION_ACCURATE = 2,
	POSITION_ESTIMATION_FAILED = 255
} Encoder_Position_State_t;

typedef enum Motor_Mode {
	TORQUE = 0, /**< @brief Starting uC.*/
	SPEED = 1
} Motor_Mode_t;

typedef enum Motor_State {
	MOTOR_STOPPED = 0, /**< @brief Starting uC.*/
	MOTOR_STARTED_IN_TORQUE_MODE = 1,
	MOTOR_STARTED_IN_SPEED_MODE = 2
} Motor_State_t;

typedef enum Heartbeat {
	HEARTBEAT_DISABLED = 0, /**< @brief Starting uC.*/
	HEARTBEAT_ENABLED = 1
} Heartbeat_t;

typedef enum Security {
	SECURITY_DISABLED = 0, /**< @brief Starting uC.*/
	SECURITY_ENABLED = 1
} Security_t;

typedef enum Node_Type {
	UNKNOWN = 0, /**< @brief Starting uC.*/
	JOINT_SMALL = 1, JOINT_BIG = 2, GRIPPER_ONE = 3, GRIPPER_TWO = 4
} Node_Type_t;

typedef enum Joint_Calibratation_State {
	JOINT_NOT_CALIBRATED = 0, /**< @brief Starting uC.*/
	JOINT_CALIBRATED = 1
} Joint_Calibratation_State_t;

typedef struct {
	FSM_State_t state;
	bool state_is_running;
	bool transition_is_running;
} __attribute__ ((packed)) FSMStatus_t;

typedef struct {
	Node_Type_t node_type;
	uint8_t can_node_id;
	Heartbeat_t hartbeat;
	Security_t security;
} __attribute__ ((packed)) NodeStatus_t;

typedef struct {
	bool termistor_exists;
	bool ma730_exists;
	bool working_area_constrain; /**< @brief settings to enable/disable constrain */
	Joint_Calibratation_State_t calibration_state;
	uint16_t gear_ratio;
	uint16_t pole_pairs;
	uint16_t maximum_electrical_rotations;
	uint16_t reachable_electrical_rotations;
	uint16_t number_of_sectors;
	int16_t  zero_electric_position;
	uint16_t zero_electric_rotation;
	double joint_working_area_in_rad; // +- hall encoder ticks of two direction torque
	uint16_t calibration_sector_size; // in electrical rotations
	uint16_t calibration_table_size;
	uint16_t calibration_table_1[1680];
	uint16_t calibration_table_2[1680];
} __attribute__ ((packed)) JointConfiguration_t;

typedef struct {
	int16_t goal;
//	int16_t last_goal;
	double  goal_motor_torque_in_nm;
	double  goal_joint_torque_in_nm;
	Motor_Mode_t mode;
	Motor_State_t state;
} __attribute__ ((packed)) MotorCommand_t;

typedef struct {
	uint16_t read_buffer;
	uint16_t angle;
	uint8_t z0;
	uint8_t z1;
	uint8_t bct;
	uint8_t ety;
	uint8_t etx;
	uint8_t ppt0;
	uint8_t ppt1;
	uint8_t ilip;
	uint8_t mglt;
	uint8_t mght;
	uint8_t rd;
	uint8_t mgh;
	uint8_t mgl;
} __attribute__ ((packed)) MA730_t;

typedef struct {
	Joint_Position_State_t current_joint_position;
	Encoder_Position_State_t encoder_position_state;

	double current_encoder_position_offset_in_rad;

	int32_t current_encoder_position;
	double current_encoder_position_in_rad;

	int16_t current_encoder_speed;
	double current_encoder_speed_in_rads;

	int32_t current_mechanical_rotation;
	int32_t current_mechanical_position;

	int32_t previous_mechanical_position;

	int32_t current_electric_rotation;

	int16_t current_electric_position;
	int16_t previous_electric_position;
	double current_joint_position_in_rad;

	double  current_joint_speed_in_rads;

	int16_t current_motor_torque;
	double  current_motor_torque_in_nm;
	double  current_joint_torque_in_nm;

	uint8_t current_temperature;
	double  current_voltage;

	uint16_t current_ma730_value;

	bool     ma730_is_running;

	uint8_t errors;
	uint8_t warnings;

	State_t stm_state_motor;
	uint16_t mc_current_faults_motor;
	uint16_t mc_occured_faults_motor;

	int16_t _current_torque_data[CURRENT_TORQUE_DATA_SIZE];
	uint8_t _current_torque_index;
} __attribute__ ((packed)) MotorStatus_t;
/* USER CODE END PTD */

/* USER CODE BEGIN PD */
// Calibrations parameters -----------------------------
#define SECTOR_SIZE 					(uint16_t) 5
#define POLE_PAIRS 						(uint16_t) 14
#define GEAR_RATIO 						(uint16_t) 121
/* USER CODE END PD */

/* USER CODE BEGIN PM */
#define NOP asm("NOP")
/* USER CODE END PM */

ADC_HandleTypeDef hadc1;
ADC_HandleTypeDef hadc2;

CORDIC_HandleTypeDef hcordic;

FDCAN_HandleTypeDef hfdcan1;

SPI_HandleTypeDef hspi2;

TIM_HandleTypeDef htim1;
TIM_HandleTypeDef htim4;
TIM_HandleTypeDef htim6;

UART_HandleTypeDef huart2;

/* USER CODE BEGIN PV */
// COUNTERS
volatile uint16_t g_can_rx_counter 	= 0;
volatile uint16_t g_can_tx_counter 	= 0;
volatile uint32_t g_counter_10000hz = 0;
volatile uint32_t g_counter_1000hz 	= 0;
volatile uint32_t g_counter_100hz 	= 0;
volatile uint32_t g_counter_10hz 	= 0;
volatile uint32_t g_counter_1hz 	= 0;
volatile uint32_t g_counter_IT 		= 0;
volatile uint32_t g_counter_main	= 0;
//volatile uint16_t g_timer_counter 	= 0;

uint8_t buff[2];

int16_t g_current_sector_number = -1;
int16_t g_current_estimated_electric_rotation = -1;

volatile NodeStatus_t 	g_node_status 		=
{
	.can_node_id = 0,
};

volatile MotorCommand_t 	g_motor_command 	=
{
	.goal = 0,
//	.last_goal = 0,
};

volatile JointConfiguration_t 	g_joint_configuration 	=
{
	.calibration_state = JOINT_NOT_CALIBRATED,
	.working_area_constrain = true,
	.termistor_exists = true,
	.ma730_exists = true,
};

volatile MotorStatus_t 	g_motor_status =
{
	.encoder_position_state = POSITION_UNKNOWN,
	.current_encoder_position_offset_in_rad = 0.0,
	.current_electric_position = 0,
	.previous_electric_position = 0,
	.current_electric_rotation = 0,
	.warnings = 0,
	.errors = 0,
	.current_ma730_value = 0,
//	.previous_ma730_value = 0,
	.ma730_is_running = false,
};

volatile MA730_t 	g_ma730 =
{
};

volatile FSMStatus_t 	g_fsm_status =
{
	.state = FSM_START,
	.state_is_running = false,
	.transition_is_running = false,
};

// FDCAN
FDCAN_FilterTypeDef   g_can_filter_config; //CAN Bus Filter
FDCAN_RxHeaderTypeDef g_can_rx_header; // CAN Bus Transmit Header
FDCAN_TxHeaderTypeDef g_can_tx_header; // CAN Bus Receive Header
uint8_t g_can_rx_data[16] = {0,0,0,0,0,0,0,0,0,0,0,0,0,0,0,0};  //CAN Bus Receive Buffer
uint8_t g_can_tx_data[12] = {0x10, 0x20, 0x30, 0x40, 0x50, 0x60, 0x70, 0x80, 0x90, 0xA0, 0xB0, 0xC0};
HAL_StatusTypeDef g_can_tx_status;

// FLASH
uint32_t g_flash_address_configuration 		= 0x08018000; // FIXME zmienic na 0x08018000
uint32_t g_flash_address_calibration_table 	= 0x08018100;
uint16_t g_calibration_config[16] = {0, 0, 0, 0, 0, 0, 0, 0, 0, 0, 0, 0, 0, 0, 0, 0};
uint32_t g_data[2] = {0, 0};

//#if defined CALIBRATION
// Calibration variables
volatile Calibration_State_t g_calibration_state = CALIBRATION_NOT_FINISHED;
volatile int32_t g_min_encoder_position = 0;
volatile int32_t g_max_encoder_position = 0;
volatile int32_t g_center_encoder_position = 0;
volatile int16_t g_max_electric_rotation_cw  = 0;
volatile int16_t g_max_electric_rotation_ccw = 0;
volatile uint16_t g_calibration_data_1_errors = 0;
volatile uint16_t g_calibration_data_2_errors = 0;
volatile uint16_t g_calibration_speed = 10; // speed of configuration rotations
volatile uint16_t g_calibration_torque = 800;
//#else
//volatile uint16_t g_current_sector_number;
volatile int16_t g_previous_sector_number = -1;
//#endif

//// ONLY FOR TESTING
//int16_t g_goal_torque;
//int16_t g_current_torque;
//uint16_t g_mc_current_faults_motor;
//uint16_t g_mc_occured_faults_motor;
//State_t g_stm_state_motor;

double g_max_voltage = 0;

/* USER CODE END PV */

void SystemClock_Config(void);
static void MX_GPIO_Init(void);
static void MX_ADC1_Init(void);
static void MX_ADC2_Init(void);
static void MX_CORDIC_Init(void);
static void MX_TIM1_Init(void);
static void MX_TIM4_Init(void);
static void MX_USART2_UART_Init(void);
static void MX_FDCAN1_Init(void);
static void MX_SPI2_Init(void);
static void MX_TIM6_Init(void);
static void MX_NVIC_Init(void);
/* USER CODE BEGIN PFP */
void Flash_Read_Data (uint32_t StartPageAddress, uint32_t *RxBuf, uint16_t numberofwords);
int16_t get_sector_number_from_electric_rotation_number(int16_t electric_rotation);
int16_t get_sector_number_from_ma730(int16_t ma730_value);
//void motor_start_in_speed_mode(int16_t speed);
//void motor_start_in_torque_mode(int16_t torque);
void motor_start(Motor_Mode_t mode, int16_t goal);
void motor_stop();
bool motor_reach_torque_limit();
bool motor_in_position(volatile int32_t position);
//#if defined CALIBRATION
bool check_calibration_data_cw(int16_t size);
bool check_calibration_data_ccw(int16_t size);
//#else
//#endif
FSM_State_t FSM_Get_State(void);
bool FSM_Set_State(FSM_State_t new_state);
bool FSM_Activate_State(FSM_State_t new_state);
bool FSM_Activate_Transition(FSM_State_t new_transition);
void MA730_ReadRegister(uint8_t reg_number);
void MA730_ReadAngle();
void MA730_WriteRegister(uint8_t reg_number, uint8_t reg_value);
uint8_t parse_cmd(void);

/* USER CODE END PFP */

int main(void)
{

  /* MCU Configuration--------------------------------------------------------*/

  /* Reset of all peripherals, Initializes the Flash interface and the Systick. */
  HAL_Init();

  /* Configure the system clock */
  SystemClock_Config();

  /* Initialize all configured peripherals */
  MX_GPIO_Init();
  MX_ADC1_Init();
  MX_ADC2_Init();
  MX_CORDIC_Init();
  MX_TIM1_Init();
  MX_TIM4_Init();
  MX_USART2_UART_Init();
  MX_MotorControl_Init();
  MX_FDCAN1_Init();
  MX_SPI2_Init();
  MX_TIM6_Init();

  /* Initialize interrupts */
  MX_NVIC_Init();
  /* USER CODE BEGIN 2 */
#if defined CALIBRATION
  g_joint_configuration.calibration_sector_size = SECTOR_SIZE;
  g_joint_configuration.pole_pairs = POLE_PAIRS;
  g_joint_configuration.gear_ratio = GEAR_RATIO;
  g_joint_configuration.maximum_electrical_rotations = g_joint_configuration.gear_ratio * g_joint_configuration.pole_pairs;
  g_joint_configuration.calibration_table_size = (uint16_t) (g_joint_configuration.maximum_electrical_rotations / g_joint_configuration.calibration_sector_size);
#else

#endif

	// Reset MA730 register to defaults
	MA730_WriteRegister(0, 0b00000000);
	MA730_WriteRegister(1, 0b00000000);
	MA730_WriteRegister(2, 0b00000000);
	MA730_WriteRegister(3, 0b00000000);
	MA730_WriteRegister(4, 0b11000000);
	MA730_WriteRegister(5, 0b11111111);
	MA730_WriteRegister(6, 0b00011100);
	MA730_WriteRegister(9, 0b00000000);

	MA730_ReadRegister(0);
	MA730_ReadRegister(1);
	MA730_ReadRegister(2);
	MA730_ReadRegister(3);
	MA730_ReadRegister(4);
	MA730_ReadRegister(5);
	MA730_ReadRegister(6);
	MA730_ReadRegister(9);

	HAL_TIM_Base_Start_IT(&htim6); // Enable 10 kHz timer // Stop to check MA730

  /* USER CODE END 2 */

  /* Infinite loop */
  while (1)
  {

    /* USER CODE BEGIN 3 */
//	MA730_ReadRegister(0x1b);
	g_counter_main++;
  }
  /* USER CODE END 3 */
}

void SystemClock_Config(void)
{
  RCC_OscInitTypeDef RCC_OscInitStruct = {0};
  RCC_ClkInitTypeDef RCC_ClkInitStruct = {0};
  RCC_PeriphCLKInitTypeDef PeriphClkInit = {0};

  /** Configure the main internal regulator output voltage
  */
  HAL_PWREx_ControlVoltageScaling(PWR_REGULATOR_VOLTAGE_SCALE1_BOOST);
  /** Initializes the RCC Oscillators according to the specified parameters
  * in the RCC_OscInitTypeDef structure.
  */
  RCC_OscInitStruct.OscillatorType = RCC_OSCILLATORTYPE_HSE;
  RCC_OscInitStruct.HSEState = RCC_HSE_ON;
  RCC_OscInitStruct.PLL.PLLState = RCC_PLL_ON;
  RCC_OscInitStruct.PLL.PLLSource = RCC_PLLSOURCE_HSE;
  RCC_OscInitStruct.PLL.PLLM = RCC_PLLM_DIV4;
  RCC_OscInitStruct.PLL.PLLN = 80;
  RCC_OscInitStruct.PLL.PLLP = RCC_PLLP_DIV8;
  RCC_OscInitStruct.PLL.PLLQ = RCC_PLLQ_DIV2;
  RCC_OscInitStruct.PLL.PLLR = RCC_PLLR_DIV2;
  if (HAL_RCC_OscConfig(&RCC_OscInitStruct) != HAL_OK)
  {
    Error_Handler();
  }
  /** Initializes the CPU, AHB and APB buses clocks
  */
  RCC_ClkInitStruct.ClockType = RCC_CLOCKTYPE_HCLK|RCC_CLOCKTYPE_SYSCLK
                              |RCC_CLOCKTYPE_PCLK1|RCC_CLOCKTYPE_PCLK2;
  RCC_ClkInitStruct.SYSCLKSource = RCC_SYSCLKSOURCE_PLLCLK;
  RCC_ClkInitStruct.AHBCLKDivider = RCC_SYSCLK_DIV1;
  RCC_ClkInitStruct.APB1CLKDivider = RCC_HCLK_DIV1;
  RCC_ClkInitStruct.APB2CLKDivider = RCC_HCLK_DIV1;

  if (HAL_RCC_ClockConfig(&RCC_ClkInitStruct, FLASH_LATENCY_4) != HAL_OK)
  {
    Error_Handler();
  }
  /** Initializes the peripherals clocks
  */
  PeriphClkInit.PeriphClockSelection = RCC_PERIPHCLK_USART2|RCC_PERIPHCLK_ADC12
                              |RCC_PERIPHCLK_FDCAN;
  PeriphClkInit.Usart2ClockSelection = RCC_USART2CLKSOURCE_PCLK1;
  PeriphClkInit.FdcanClockSelection = RCC_FDCANCLKSOURCE_PCLK1;
  PeriphClkInit.Adc12ClockSelection = RCC_ADC12CLKSOURCE_PLL;
  if (HAL_RCCEx_PeriphCLKConfig(&PeriphClkInit) != HAL_OK)
  {
    Error_Handler();
  }
}

/**
  * @brief NVIC Configuration.
  * @retval None
  */
static void MX_NVIC_Init(void)
{
  /* TIM1_BRK_TIM15_IRQn interrupt configuration */
  HAL_NVIC_SetPriority(TIM1_BRK_TIM15_IRQn, 4, 1);
  HAL_NVIC_EnableIRQ(TIM1_BRK_TIM15_IRQn);
  /* TIM1_UP_TIM16_IRQn interrupt configuration */
  HAL_NVIC_SetPriority(TIM1_UP_TIM16_IRQn, 0, 0);
  HAL_NVIC_EnableIRQ(TIM1_UP_TIM16_IRQn);
  /* ADC1_2_IRQn interrupt configuration */
  HAL_NVIC_SetPriority(ADC1_2_IRQn, 2, 0);
  HAL_NVIC_EnableIRQ(ADC1_2_IRQn);
  /* TIM4_IRQn interrupt configuration */
  HAL_NVIC_SetPriority(TIM4_IRQn, 3, 0);
  HAL_NVIC_EnableIRQ(TIM4_IRQn);
  /* USART2_IRQn interrupt configuration */
  HAL_NVIC_SetPriority(USART2_IRQn, 3, 1);
  HAL_NVIC_EnableIRQ(USART2_IRQn);
}

static void MX_ADC1_Init(void)
{

  ADC_MultiModeTypeDef multimode = {0};
  ADC_InjectionConfTypeDef sConfigInjected = {0};

  /** Common config
  */
  hadc1.Instance = ADC1;
  hadc1.Init.ClockPrescaler = ADC_CLOCK_ASYNC_DIV4;
  hadc1.Init.Resolution = ADC_RESOLUTION_12B;
  hadc1.Init.DataAlign = ADC_DATAALIGN_LEFT;
  hadc1.Init.GainCompensation = 0;
  hadc1.Init.ScanConvMode = ADC_SCAN_ENABLE;
  hadc1.Init.EOCSelection = ADC_EOC_SINGLE_CONV;
  hadc1.Init.LowPowerAutoWait = DISABLE;
  hadc1.Init.ContinuousConvMode = DISABLE;
  hadc1.Init.NbrOfConversion = 1;
  hadc1.Init.DiscontinuousConvMode = DISABLE;
  hadc1.Init.DMAContinuousRequests = DISABLE;
  hadc1.Init.Overrun = ADC_OVR_DATA_PRESERVED;
  hadc1.Init.OversamplingMode = DISABLE;
  if (HAL_ADC_Init(&hadc1) != HAL_OK)
  {
    Error_Handler();
  }
  /** Configure the ADC multi-mode
  */
  multimode.Mode = ADC_MODE_INDEPENDENT;
  if (HAL_ADCEx_MultiModeConfigChannel(&hadc1, &multimode) != HAL_OK)
  {
    Error_Handler();
  }
  /** Configure Injected Channel
  */
  sConfigInjected.InjectedChannel = ADC_CHANNEL_2;
  sConfigInjected.InjectedRank = ADC_INJECTED_RANK_1;
  sConfigInjected.InjectedSamplingTime = ADC_SAMPLETIME_6CYCLES_5;
  sConfigInjected.InjectedSingleDiff = ADC_SINGLE_ENDED;
  sConfigInjected.InjectedOffsetNumber = ADC_OFFSET_NONE;
  sConfigInjected.InjectedOffset = 0;
  sConfigInjected.InjectedNbrOfConversion = 2;
  sConfigInjected.InjectedDiscontinuousConvMode = DISABLE;
  sConfigInjected.AutoInjectedConv = DISABLE;
  sConfigInjected.QueueInjectedContext = DISABLE;
  sConfigInjected.ExternalTrigInjecConv = ADC_EXTERNALTRIGINJEC_T1_TRGO;
  sConfigInjected.ExternalTrigInjecConvEdge = ADC_EXTERNALTRIGINJECCONV_EDGE_RISING;
  sConfigInjected.InjecOversamplingMode = DISABLE;
  if (HAL_ADCEx_InjectedConfigChannel(&hadc1, &sConfigInjected) != HAL_OK)
  {
    Error_Handler();
  }
  /** Configure Injected Channel
  */
  sConfigInjected.InjectedChannel = ADC_CHANNEL_14;
  sConfigInjected.InjectedRank = ADC_INJECTED_RANK_2;
  if (HAL_ADCEx_InjectedConfigChannel(&hadc1, &sConfigInjected) != HAL_OK)
  {
    Error_Handler();
  }

}

static void MX_ADC2_Init(void)
{

  ADC_InjectionConfTypeDef sConfigInjected = {0};
  ADC_ChannelConfTypeDef sConfig = {0};

  /** Common config
  */
  hadc2.Instance = ADC2;
  hadc2.Init.ClockPrescaler = ADC_CLOCK_ASYNC_DIV4;
  hadc2.Init.Resolution = ADC_RESOLUTION_12B;
  hadc2.Init.DataAlign = ADC_DATAALIGN_LEFT;
  hadc2.Init.GainCompensation = 0;
  hadc2.Init.ScanConvMode = ADC_SCAN_ENABLE;
  hadc2.Init.EOCSelection = ADC_EOC_SINGLE_CONV;
  hadc2.Init.LowPowerAutoWait = DISABLE;
  hadc2.Init.ContinuousConvMode = DISABLE;
  hadc2.Init.NbrOfConversion = 2;
  hadc2.Init.DiscontinuousConvMode = DISABLE;
  hadc2.Init.ExternalTrigConv = ADC_SOFTWARE_START;
  hadc2.Init.ExternalTrigConvEdge = ADC_EXTERNALTRIGCONVEDGE_NONE;
  hadc2.Init.DMAContinuousRequests = DISABLE;
  hadc2.Init.Overrun = ADC_OVR_DATA_PRESERVED;
  hadc2.Init.OversamplingMode = DISABLE;
  if (HAL_ADC_Init(&hadc2) != HAL_OK)
  {
    Error_Handler();
  }
  /** Configure Injected Channel
  */
  sConfigInjected.InjectedChannel = ADC_CHANNEL_14;
  sConfigInjected.InjectedRank = ADC_INJECTED_RANK_1;
  sConfigInjected.InjectedSamplingTime = ADC_SAMPLETIME_6CYCLES_5;
  sConfigInjected.InjectedSingleDiff = ADC_SINGLE_ENDED;
  sConfigInjected.InjectedOffsetNumber = ADC_OFFSET_NONE;
  sConfigInjected.InjectedOffset = 0;
  sConfigInjected.InjectedNbrOfConversion = 2;
  sConfigInjected.InjectedDiscontinuousConvMode = DISABLE;
  sConfigInjected.AutoInjectedConv = DISABLE;
  sConfigInjected.QueueInjectedContext = DISABLE;
  sConfigInjected.ExternalTrigInjecConv = ADC_EXTERNALTRIGINJEC_T1_TRGO;
  sConfigInjected.ExternalTrigInjecConvEdge = ADC_EXTERNALTRIGINJECCONV_EDGE_RISING;
  sConfigInjected.InjecOversamplingMode = DISABLE;
  if (HAL_ADCEx_InjectedConfigChannel(&hadc2, &sConfigInjected) != HAL_OK)
  {
    Error_Handler();
  }
  /** Configure Injected Channel
  */
  sConfigInjected.InjectedChannel = ADC_CHANNEL_3;
  sConfigInjected.InjectedRank = ADC_INJECTED_RANK_2;
  if (HAL_ADCEx_InjectedConfigChannel(&hadc2, &sConfigInjected) != HAL_OK)
  {
    Error_Handler();
  }
  /** Configure Regular Channel
  */
  sConfig.Channel = ADC_CHANNEL_1;
  sConfig.Rank = ADC_REGULAR_RANK_1;
  sConfig.SamplingTime = ADC_SAMPLETIME_47CYCLES_5;
  sConfig.SingleDiff = ADC_SINGLE_ENDED;
  sConfig.OffsetNumber = ADC_OFFSET_NONE;
  sConfig.Offset = 0;
  if (HAL_ADC_ConfigChannel(&hadc2, &sConfig) != HAL_OK)
  {
    Error_Handler();
  }
  /** Configure Regular Channel
  */
  sConfig.Channel = ADC_CHANNEL_13;
  sConfig.Rank = ADC_REGULAR_RANK_2;
  if (HAL_ADC_ConfigChannel(&hadc2, &sConfig) != HAL_OK)
  {
    Error_Handler();
  }

}

static void MX_CORDIC_Init(void)
{

  hcordic.Instance = CORDIC;
  if (HAL_CORDIC_Init(&hcordic) != HAL_OK)
  {
    Error_Handler();
  }

}

static void MX_FDCAN1_Init(void)
{

  hfdcan1.Instance = FDCAN1;
  hfdcan1.Init.ClockDivider = FDCAN_CLOCK_DIV2;
  hfdcan1.Init.FrameFormat = FDCAN_FRAME_FD_BRS;
  hfdcan1.Init.Mode = FDCAN_MODE_NORMAL;
  hfdcan1.Init.AutoRetransmission = ENABLE;
  hfdcan1.Init.TransmitPause = ENABLE;
  hfdcan1.Init.ProtocolException = DISABLE;
  hfdcan1.Init.NominalPrescaler = 5;
  hfdcan1.Init.NominalSyncJumpWidth = 3;
  hfdcan1.Init.NominalTimeSeg1 = 12;
  hfdcan1.Init.NominalTimeSeg2 = 3;
  hfdcan1.Init.DataPrescaler = 1;
  hfdcan1.Init.DataSyncJumpWidth = 3;
  hfdcan1.Init.DataTimeSeg1 = 12;
  hfdcan1.Init.DataTimeSeg2 = 3;
  hfdcan1.Init.StdFiltersNbr = 1;
  hfdcan1.Init.ExtFiltersNbr = 0;
  hfdcan1.Init.TxFifoQueueMode = FDCAN_TX_FIFO_OPERATION;
  if (HAL_FDCAN_Init(&hfdcan1) != HAL_OK)
  {
    Error_Handler();
  }

}

static void MX_SPI2_Init(void)
{

  /* SPI2 parameter configuration*/
  hspi2.Instance = SPI2;
  hspi2.Init.Mode = SPI_MODE_MASTER;
  hspi2.Init.Direction = SPI_DIRECTION_2LINES;
  hspi2.Init.DataSize = SPI_DATASIZE_16BIT;
  hspi2.Init.CLKPolarity = SPI_POLARITY_LOW;
  hspi2.Init.CLKPhase = SPI_PHASE_1EDGE;
  hspi2.Init.NSS = SPI_NSS_SOFT;
  hspi2.Init.BaudRatePrescaler = SPI_BAUDRATEPRESCALER_16;
  hspi2.Init.FirstBit = SPI_FIRSTBIT_MSB;
  hspi2.Init.TIMode = SPI_TIMODE_DISABLE;
  hspi2.Init.CRCCalculation = SPI_CRCCALCULATION_DISABLE;
  hspi2.Init.CRCPolynomial = 7;
  hspi2.Init.CRCLength = SPI_CRC_LENGTH_DATASIZE;
  hspi2.Init.NSSPMode = SPI_NSS_PULSE_ENABLE;
  if (HAL_SPI_Init(&hspi2) != HAL_OK)
  {
    Error_Handler();
  }

}

static void MX_TIM1_Init(void)
{

  TIM_SlaveConfigTypeDef sSlaveConfig = {0};
  TIM_MasterConfigTypeDef sMasterConfig = {0};
  TIM_OC_InitTypeDef sConfigOC = {0};
  TIM_BreakDeadTimeConfigTypeDef sBreakDeadTimeConfig = {0};

  htim1.Instance = TIM1;
  htim1.Init.Prescaler = ((TIM_CLOCK_DIVIDER) - 1);
  htim1.Init.CounterMode = TIM_COUNTERMODE_CENTERALIGNED1;
  htim1.Init.Period = ((PWM_PERIOD_CYCLES) / 2);
  htim1.Init.ClockDivision = TIM_CLOCKDIVISION_DIV2;
  htim1.Init.RepetitionCounter = (REP_COUNTER);
  htim1.Init.AutoReloadPreload = TIM_AUTORELOAD_PRELOAD_DISABLE;
  if (HAL_TIM_Base_Init(&htim1) != HAL_OK)
  {
    Error_Handler();
  }
  if (HAL_TIM_PWM_Init(&htim1) != HAL_OK)
  {
    Error_Handler();
  }
  sSlaveConfig.SlaveMode = TIM_SLAVEMODE_TRIGGER;
  sSlaveConfig.InputTrigger = TIM_TS_ITR1;
  if (HAL_TIM_SlaveConfigSynchro(&htim1, &sSlaveConfig) != HAL_OK)
  {
    Error_Handler();
  }
  sMasterConfig.MasterOutputTrigger = TIM_TRGO_OC4REF;
  sMasterConfig.MasterOutputTrigger2 = TIM_TRGO2_RESET;
  sMasterConfig.MasterSlaveMode = TIM_MASTERSLAVEMODE_DISABLE;
  if (HAL_TIMEx_MasterConfigSynchronization(&htim1, &sMasterConfig) != HAL_OK)
  {
    Error_Handler();
  }
  sConfigOC.OCMode = TIM_OCMODE_PWM1;
  sConfigOC.Pulse = 0;
  sConfigOC.OCPolarity = TIM_OCPOLARITY_HIGH;
  sConfigOC.OCNPolarity = TIM_OCNPOLARITY_HIGH;
  sConfigOC.OCFastMode = TIM_OCFAST_DISABLE;
  sConfigOC.OCIdleState = TIM_OCIDLESTATE_RESET;
  sConfigOC.OCNIdleState = TIM_OCNIDLESTATE_RESET;
  if (HAL_TIM_PWM_ConfigChannel(&htim1, &sConfigOC, TIM_CHANNEL_1) != HAL_OK)
  {
    Error_Handler();
  }
  if (HAL_TIM_PWM_ConfigChannel(&htim1, &sConfigOC, TIM_CHANNEL_2) != HAL_OK)
  {
    Error_Handler();
  }
  if (HAL_TIM_PWM_ConfigChannel(&htim1, &sConfigOC, TIM_CHANNEL_3) != HAL_OK)
  {
    Error_Handler();
  }
  sConfigOC.OCMode = TIM_OCMODE_PWM2;
  if (HAL_TIM_PWM_ConfigChannel(&htim1, &sConfigOC, TIM_CHANNEL_4) != HAL_OK)
  {
    Error_Handler();
  }
  sBreakDeadTimeConfig.OffStateRunMode = TIM_OSSR_ENABLE;
  sBreakDeadTimeConfig.OffStateIDLEMode = TIM_OSSI_ENABLE;
  sBreakDeadTimeConfig.LockLevel = TIM_LOCKLEVEL_1;
  sBreakDeadTimeConfig.DeadTime = ((DEAD_TIME_COUNTS) / 2);
  sBreakDeadTimeConfig.BreakState = TIM_BREAK_DISABLE;
  sBreakDeadTimeConfig.BreakPolarity = TIM_BREAKPOLARITY_LOW;
  sBreakDeadTimeConfig.BreakFilter = 0;
  sBreakDeadTimeConfig.BreakAFMode = TIM_BREAK_AFMODE_INPUT;
  sBreakDeadTimeConfig.Break2State = TIM_BREAK2_DISABLE;
  sBreakDeadTimeConfig.Break2Polarity = TIM_BREAK2POLARITY_HIGH;
  sBreakDeadTimeConfig.Break2Filter = 0;
  sBreakDeadTimeConfig.Break2AFMode = TIM_BREAK_AFMODE_INPUT;
  sBreakDeadTimeConfig.AutomaticOutput = TIM_AUTOMATICOUTPUT_DISABLE;
  if (HAL_TIMEx_ConfigBreakDeadTime(&htim1, &sBreakDeadTimeConfig) != HAL_OK)
  {
    Error_Handler();
  }
  HAL_TIM_MspPostInit(&htim1);

}

static void MX_TIM4_Init(void)
{

  TIM_Encoder_InitTypeDef sConfig = {0};
  TIM_MasterConfigTypeDef sMasterConfig = {0};

  htim4.Instance = TIM4;
  htim4.Init.Prescaler = 0;
  htim4.Init.CounterMode = TIM_COUNTERMODE_UP;
  htim4.Init.Period = M1_PULSE_NBR;
  htim4.Init.ClockDivision = TIM_CLOCKDIVISION_DIV1;
  htim4.Init.AutoReloadPreload = TIM_AUTORELOAD_PRELOAD_DISABLE;
  sConfig.EncoderMode = TIM_ENCODERMODE_TI12;
  sConfig.IC1Polarity = TIM_ICPOLARITY_RISING;
  sConfig.IC1Selection = TIM_ICSELECTION_DIRECTTI;
  sConfig.IC1Prescaler = TIM_ICPSC_DIV1;
  sConfig.IC1Filter = M1_ENC_IC_FILTER;
  sConfig.IC2Polarity = TIM_ICPOLARITY_RISING;
  sConfig.IC2Selection = TIM_ICSELECTION_DIRECTTI;
  sConfig.IC2Prescaler = TIM_ICPSC_DIV1;
  sConfig.IC2Filter = M1_ENC_IC_FILTER;
  if (HAL_TIM_Encoder_Init(&htim4, &sConfig) != HAL_OK)
  {
    Error_Handler();
  }
  sMasterConfig.MasterOutputTrigger = TIM_TRGO_RESET;
  sMasterConfig.MasterSlaveMode = TIM_MASTERSLAVEMODE_DISABLE;
  if (HAL_TIMEx_MasterConfigSynchronization(&htim4, &sMasterConfig) != HAL_OK)
  {
    Error_Handler();
  }

}

static void MX_TIM6_Init(void)
{

  TIM_MasterConfigTypeDef sMasterConfig = {0};

  htim6.Instance = TIM6;
  htim6.Init.Prescaler = 0;
  htim6.Init.CounterMode = TIM_COUNTERMODE_UP;
  htim6.Init.Period = 15999;
  htim6.Init.AutoReloadPreload = TIM_AUTORELOAD_PRELOAD_DISABLE;
  if (HAL_TIM_Base_Init(&htim6) != HAL_OK)
  {
    Error_Handler();
  }
  sMasterConfig.MasterOutputTrigger = TIM_TRGO_RESET;
  sMasterConfig.MasterSlaveMode = TIM_MASTERSLAVEMODE_DISABLE;
  if (HAL_TIMEx_MasterConfigSynchronization(&htim6, &sMasterConfig) != HAL_OK)
  {
    Error_Handler();
  }

}

static void MX_USART2_UART_Init(void)
{

  huart2.Instance = USART2;
  huart2.Init.BaudRate = 115200;
  huart2.Init.WordLength = UART_WORDLENGTH_8B;
  huart2.Init.StopBits = UART_STOPBITS_1;
  huart2.Init.Parity = UART_PARITY_NONE;
  huart2.Init.Mode = UART_MODE_TX_RX;
  huart2.Init.HwFlowCtl = UART_HWCONTROL_NONE;
  huart2.Init.OverSampling = UART_OVERSAMPLING_16;
  huart2.Init.OneBitSampling = UART_ONE_BIT_SAMPLE_DISABLE;
  huart2.Init.ClockPrescaler = UART_PRESCALER_DIV1;
  huart2.AdvancedInit.AdvFeatureInit = UART_ADVFEATURE_NO_INIT;
  if (HAL_UART_Init(&huart2) != HAL_OK)
  {
    Error_Handler();
  }
  if (HAL_UARTEx_SetTxFifoThreshold(&huart2, UART_TXFIFO_THRESHOLD_1_8) != HAL_OK)
  {
    Error_Handler();
  }
  if (HAL_UARTEx_SetRxFifoThreshold(&huart2, UART_RXFIFO_THRESHOLD_1_8) != HAL_OK)
  {
    Error_Handler();
  }
  if (HAL_UARTEx_DisableFifoMode(&huart2) != HAL_OK)
  {
    Error_Handler();
  }

}

static void MX_GPIO_Init(void)
{
  GPIO_InitTypeDef GPIO_InitStruct = {0};

  /* GPIO Ports Clock Enable */
  __HAL_RCC_GPIOC_CLK_ENABLE();
  __HAL_RCC_GPIOF_CLK_ENABLE();
  __HAL_RCC_GPIOA_CLK_ENABLE();
  __HAL_RCC_GPIOB_CLK_ENABLE();

  /*Configure GPIO pin Output Level */
  HAL_GPIO_WritePin(GPIOB, MA730_CS_Pin|SEC_OUT_Pin, GPIO_PIN_RESET);

  /*Configure GPIO pins : DIP2_Pin DIP1_Pin SEC_IN_Pin */
  GPIO_InitStruct.Pin = DIP2_Pin|DIP1_Pin|SEC_IN_Pin;
  GPIO_InitStruct.Mode = GPIO_MODE_INPUT;
  GPIO_InitStruct.Pull = GPIO_NOPULL;
  HAL_GPIO_Init(GPIOC, &GPIO_InitStruct);

  /*Configure GPIO pins : MA730_CS_Pin SEC_OUT_Pin */
  GPIO_InitStruct.Pin = MA730_CS_Pin|SEC_OUT_Pin;
  GPIO_InitStruct.Mode = GPIO_MODE_OUTPUT_PP;
  GPIO_InitStruct.Pull = GPIO_NOPULL;
  GPIO_InitStruct.Speed = GPIO_SPEED_FREQ_LOW;
  HAL_GPIO_Init(GPIOB, &GPIO_InitStruct);

  /*Configure GPIO pins : DIP4_Pin DIP3_Pin */
  GPIO_InitStruct.Pin = DIP4_Pin|DIP3_Pin;
  GPIO_InitStruct.Mode = GPIO_MODE_INPUT;
  GPIO_InitStruct.Pull = GPIO_NOPULL;
  HAL_GPIO_Init(GPIOB, &GPIO_InitStruct);

}

/* USER CODE BEGIN 4 */
void HAL_TIM_PeriodElapsedCallback(TIM_HandleTypeDef *htim)
{
//	return;
	static uint16_t g_timer_counter = 0;

	if(htim->Instance == TIM6) // 10 000 Hz
	{

		// 10 000 Hz
		{
			g_counter_10000hz++;

			// CALCULATE CHANGE ELECTRIC ROTATION
			g_motor_status.previous_electric_position = g_motor_status.current_electric_position; // store old position
			g_motor_status.current_electric_position = ENCODER_M1._Super.hElAngle;

			if (g_motor_status.previous_electric_position > 28000 && g_motor_status.current_electric_position < - 28000)
			{
				g_motor_status.current_electric_rotation++;
			}
			if (g_motor_status.current_electric_position > 28000  && g_motor_status.previous_electric_position < - 28000)
			{
				g_motor_status.current_electric_rotation--;
			}

			// READ POSITION
			g_motor_status.previous_mechanical_position = g_motor_status.current_mechanical_position; // store old position
			g_motor_status.current_mechanical_position = ENCODER_M1.PreviousCapture; // 0 ... 14336 - 1 mechanical motor rotation

			if (g_motor_status.previous_mechanical_position > ENCODER_M1.PulseNumber - 4000 && g_motor_status.current_mechanical_position  < 4000)
			{
				g_motor_status.current_mechanical_rotation++;
			}
			if (g_motor_status.current_mechanical_position  > ENCODER_M1.PulseNumber - 4000 && g_motor_status.previous_mechanical_position < 4000)
			{
				g_motor_status.current_mechanical_rotation--;
			}

			// READ SPEED
			g_motor_status.current_encoder_speed = ENCODER_M1._Super.hAvrMecSpeedUnit;
			g_motor_status.current_encoder_speed_in_rads = g_motor_status.current_encoder_speed * 6 * M_TWOPI / 60;

//			g_motor_status.current_joint_speed_in_rads = g_motor_status.current_encoder_speed / g_joint_configuration.gear_ratio;
			g_motor_status.current_joint_speed_in_rads = g_motor_status.current_encoder_speed_in_rads / 120.0;

			// READ TORQUE
			g_motor_status._current_torque_data[g_motor_status._current_torque_index++] = MC_GetPhaseCurrentAmplitudeMotor1();
			g_motor_status._current_torque_index %= CURRENT_TORQUE_DATA_SIZE;

			// ERRORS:
			// 1. SPEED  (pi/2 rads)
//			if (g_motor_status.current_joint_speed_in_rads > M_PI_2 || g_motor_status.current_joint_speed_in_rads < -1 * M_PI_2)
//			{
//				// STOP MOTOR - SPEED IS TO HIGH
//				g_motor_status.errors = g_motor_status.errors | JOINT_JOINT_SPEED_TO_HIGH;
//				FSM_Activate_State(FSM_FAULT_REACTION_ACTIVE);
//			}
			// 2. TORQUE (256 Nm)
			// 3. TEMP

			// WARNINGS:
			// WORKING AREA
			if (g_motor_status.current_joint_position_in_rad < -1 * g_joint_configuration.joint_working_area_in_rad && g_joint_configuration.working_area_constrain)
			{
				g_motor_status.current_joint_position = POSITION_UNDER_WORKING_AREA;
				g_motor_status.warnings = g_motor_status.warnings | JOINT_OUTSIDE_WORKING_AREA;
			}
			else if(g_motor_status.current_joint_position_in_rad > g_joint_configuration.joint_working_area_in_rad && g_joint_configuration.working_area_constrain)
			{
				g_motor_status.current_joint_position = POSITION_OVER_WORKING_AREA;
				g_motor_status.warnings = g_motor_status.warnings | JOINT_OUTSIDE_WORKING_AREA;
			}
			else
			{
				g_motor_status.current_joint_position = POSITION_IN_WORKING_AREA;
				g_motor_status.warnings = g_motor_status.warnings & (0xFF ^ JOINT_OUTSIDE_WORKING_AREA);
			}

			// ENCODER_NOT_ACCURATE
			if (g_motor_status.encoder_position_state != POSITION_ACCURATE)
			{
				g_motor_status.warnings = g_motor_status.warnings | JOINT_POSITION_NOT_ACCURATE;

			}
			else
			{
				g_motor_status.warnings = g_motor_status.warnings & (0xFF ^ JOINT_POSITION_NOT_ACCURATE);
			}

		}

		// 1000 Hz
		if (g_timer_counter % 10 == 0)
		{
			g_counter_1000hz++;

			g_motor_status.current_encoder_position = g_motor_status.current_mechanical_rotation * ENCODER_M1.PulseNumber + g_motor_status.current_mechanical_position;

			g_motor_status.current_encoder_position_in_rad = M_TWOPI * (double) g_motor_status.current_encoder_position / ENCODER_M1.PulseNumber;
			g_motor_status.current_joint_position_in_rad = g_motor_status.current_encoder_position_in_rad / g_joint_configuration.gear_ratio + g_motor_status.current_encoder_position_offset_in_rad;

			// Get states
//			g_motor_status.current_voltage 			= (double) RealBusVoltageSensorParamsM1.aBuffer[RealBusVoltageSensorParamsM1.index] / 1225; // FIXME sprawdzic jak to jest interpretowane
			g_motor_status.current_voltage 			= (double) RealBusVoltageSensorParamsM1.aBuffer[RealBusVoltageSensorParamsM1.index] / 1225; // FIXME sprawdzic jak to jest interpretowane
			if (g_max_voltage < g_motor_status.current_voltage) {
				g_max_voltage = g_motor_status.current_voltage;
			}
			g_motor_status.stm_state_motor 			= MC_GetSTMStateMotor1();
			g_motor_status.mc_current_faults_motor 	= MC_GetCurrentFaultsMotor1();
			g_motor_status.mc_occured_faults_motor 	= MC_GetOccurredFaultsMotor1();
			g_motor_status.current_temperature 		= (uint8_t) NTC_GetAvTemp_C(&TempSensorParamsM1);

			g_motor_command.goal_motor_torque_in_nm = g_motor_command.goal_joint_torque_in_nm / g_joint_configuration.gear_ratio;
			g_motor_command.goal					= (((double) g_motor_command.goal_motor_torque_in_nm) * 32768.0) / (33.0 * 0.1118);

			// CURRENT TORQUE
			double temp_torque = 0;
			for (int i = 0; i < CURRENT_TORQUE_DATA_SIZE; i++)
			{
				temp_torque += (double) g_motor_status._current_torque_data[i];
			}
			g_motor_status.current_motor_torque 		= (int16_t) (temp_torque / CURRENT_TORQUE_DATA_SIZE);
			g_motor_status.current_motor_torque_in_nm	= (((double) g_motor_status.current_motor_torque) / 32768.0) * 33.0 * 0.1118;
			g_motor_status.current_joint_torque_in_nm	= g_motor_status.current_motor_torque_in_nm * g_joint_configuration.gear_ratio;

			// READ MA730 Position
			if (g_joint_configuration.ma730_exists)
			{
				if (g_counter_1hz > 1) // wait 1 sec to analyse data
				{
					g_motor_status.ma730_is_running = true;
					MA730_ReadAngle();
					g_motor_status.current_ma730_value = g_ma730.angle;
				}
			}

			if (g_motor_status.ma730_is_running == true && g_joint_configuration.calibration_state == JOINT_CALIBRATED)
			{
				// JOINT POSITION ESTIMATION
				switch (g_motor_status.encoder_position_state)
				{
					case POSITION_ESTIMATION_FAILED:
					{
						// RAISE ERROR
						break;
					}

					case POSITION_ACCURATE:
					{
						break;
					}

					case POSITION_APROXIMATED:
					{
						g_current_sector_number = get_sector_number_from_ma730(g_motor_status.current_ma730_value);
						// If motor running and sector is change update
						if (g_current_sector_number != g_previous_sector_number && g_previous_sector_number != -1) // pass 1 time, to load previous and current
						{
							double electric_rotation_width = M_TWOPI / (g_joint_configuration.pole_pairs * g_joint_configuration.gear_ratio);
							uint16_t l_current_electric_rotation;

							if (g_current_sector_number - g_previous_sector_number > 0)
							{ // rotation in CCW direction => "+"
								l_current_electric_rotation = (g_current_sector_number) * g_joint_configuration.calibration_sector_size;
							}
							else
							{ // rotation in CW direction ==> "-"
								l_current_electric_rotation = (g_current_sector_number + 1) * g_joint_configuration.calibration_sector_size - 1;
							}
							int32_t l_diff_electric_position = g_joint_configuration.zero_electric_position - g_motor_status.current_electric_position;

							g_motor_status.current_encoder_position_offset_in_rad = -1 * ((g_joint_configuration.zero_electric_rotation - l_current_electric_rotation) + ( (double) l_diff_electric_position / 65536) - 1.0) * electric_rotation_width;

							g_motor_status.encoder_position_state = POSITION_ACCURATE;
						}

						g_previous_sector_number = g_current_sector_number;
						break;
					}
//
					case POSITION_UNKNOWN:
					{
						g_current_sector_number = get_sector_number_from_ma730(g_motor_status.current_ma730_value);
						if (g_current_sector_number != -1)
						{
							double electric_rotation_width = M_TWOPI / (g_joint_configuration.pole_pairs * g_joint_configuration.gear_ratio);

			//				g_zero_sector_number = get_sector_number_from_electric_rotation_number(g_joint_configuration.zero_electric_rotation);
							g_current_estimated_electric_rotation = g_current_sector_number *  g_joint_configuration.calibration_sector_size; // center current sector

							g_motor_status.current_encoder_position_offset_in_rad = -1 * (g_joint_configuration.zero_electric_rotation - g_current_estimated_electric_rotation) * electric_rotation_width;

							// calculate encoder positioon offset
							g_motor_status.encoder_position_state = POSITION_APROXIMATED;
						}
						break;
					}
				}

			}

			// FSM
			switch (FSM_Get_State()) {

//				case FSM_START:
//				{
//					g_center_encoder_position = -1;
//					g_fsm_status.state = FSM_CALIBRATION_PHASE_1;
//					break;
//				}

				case FSM_CALIBRATION_PHASE_1:
				{

					if (motor_reach_torque_limit()) // REACH MINIMUM EDGE
					{
						motor_stop();
						g_motor_status.current_electric_rotation = 0; // zeroing electric rotation counter
						g_min_encoder_position = g_motor_status.current_encoder_position; // encoder value

						g_fsm_status.state = FSM_CALIBRATION_PHASE_2;

					}
					else
					{
						motor_start(SPEED, -1 * g_calibration_speed);
					}

					break;
				}

				case FSM_CALIBRATION_PHASE_2:
				{
					if (g_motor_status.current_electric_rotation % g_joint_configuration.calibration_sector_size == (0) &&
							g_joint_configuration.calibration_table_1[g_motor_status.current_electric_rotation / g_joint_configuration.calibration_sector_size] == 0)
					{
						g_joint_configuration.calibration_table_1[g_motor_status.current_electric_rotation / g_joint_configuration.calibration_sector_size] = g_motor_status.current_ma730_value;
					}

					if (motor_reach_torque_limit()) // REACH MAXIMUM EDGE
					{
						motor_stop();
						g_joint_configuration.calibration_table_2[g_motor_status.current_electric_rotation / g_joint_configuration.calibration_sector_size] = g_motor_status.current_ma730_value;
						g_max_electric_rotation_cw 	= g_motor_status.current_electric_rotation; // max electric rotation counter

						g_max_encoder_position = g_motor_status.current_encoder_position; // max encoder value
						g_fsm_status.state = FSM_CALIBRATION_PHASE_3;

					}
					else
					{
						motor_start(SPEED, g_calibration_speed);
					}

					break;
				}

				case FSM_CALIBRATION_PHASE_3:
				{
					if (g_motor_status.current_electric_rotation % g_joint_configuration.calibration_sector_size == (g_joint_configuration.calibration_sector_size - 1) &&
							g_joint_configuration.calibration_table_2[g_motor_status.current_electric_rotation / g_joint_configuration.calibration_sector_size] == 0)
					{
						g_joint_configuration.calibration_table_2[g_motor_status.current_electric_rotation / g_joint_configuration.calibration_sector_size] = g_motor_status.current_ma730_value;
					}

					if (motor_reach_torque_limit()) // REACH MINIMUM EDGE
					{
						motor_stop();
						g_joint_configuration.calibration_table_1[g_motor_status.current_electric_rotation / g_joint_configuration.calibration_sector_size] = g_motor_status.current_ma730_value;
		  //				g_fsm_current_state = CALIBRATION_FINISHED_WITH_SUCCESS;
						g_fsm_status.state = FSM_CALIBRATION_PHASE_4;

					}
					else
					{
						motor_start(SPEED, -1 * g_calibration_speed);
					}

					break;
				}

				case FSM_CALIBRATION_PHASE_4:
				{
					// Sprawdzenie tablicy kalibracyjnej
					if (!check_calibration_data_cw(g_max_electric_rotation_cw / g_joint_configuration.calibration_sector_size) ||
						!check_calibration_data_ccw(g_max_electric_rotation_cw / g_joint_configuration.calibration_sector_size))
					{
						g_fsm_status.state = FSM_CALIBRATION_PHASE_2;
		  //				g_fsm_current_state = CALIBRATION_PHASE_5;
						g_calibration_state = CALIBRATION_TABLE_CONTAINS_ZEROES;
		  //				g_error_1++;
					}
					else
					{
						g_max_electric_rotation_ccw = g_motor_status.current_electric_rotation; // Should be 0 right now
		  //								g_center_hall_encoder_position = (g_max_hall_encoder_position + 1) / 2;
						g_center_encoder_position = (g_max_encoder_position - g_min_encoder_position + 1) / 2 + g_min_encoder_position;

						g_joint_configuration.number_of_sectors = (uint16_t) (g_max_electric_rotation_cw / g_joint_configuration.calibration_sector_size);
						g_joint_configuration.reachable_electrical_rotations = g_max_electric_rotation_cw;
						g_calibration_state = CALIBRATION_OK;
						g_fsm_status.state = FSM_CALIBRATION_PHASE_5;
					}
					break;
				}

				case FSM_CALIBRATION_PHASE_5:
				{
					if (motor_in_position(g_center_encoder_position))
					{
						g_fsm_status.state = FSM_CALIBRATION_PHASE_6;
						motor_start(SPEED, 0);
						motor_stop();

						g_joint_configuration.zero_electric_rotation = g_motor_status.current_electric_rotation;
						g_joint_configuration.zero_electric_position = (uint16_t) (g_motor_status.current_electric_position);
						g_joint_configuration.zero_electric_position = (int16_t) (g_motor_status.current_electric_position);
					}
					else
					{
						motor_start(SPEED, g_calibration_speed);
					}

					if (motor_reach_torque_limit()) // REACH EDGE - FAILURE
					{
						motor_start(SPEED, 0);
						motor_stop();
						g_calibration_state = MISSED_CENTER_POSITION;
//						g_fsm_status.state = FSM_STOPPED_WITH_ERRORS;
						FSM_Activate_State(FSM_FAULT_REACTION_ACTIVE);

					}

					break;
				}
				case FSM_CALIBRATION_PHASE_6:
				{
					volatile int d;
					volatile uint32_t error;

					HAL_TIM_Base_Stop_IT(&htim6); // Disable 10 kHz timer

					uint64_t data;

					HAL_FLASH_Unlock();

					FLASH_EraseInitTypeDef EraseInitStruct;
					EraseInitStruct.TypeErase 	= FLASH_TYPEERASE_PAGES;
					EraseInitStruct.Banks 		= FLASH_BANK_1;
					EraseInitStruct.Page 		= (g_flash_address_configuration & 0x07FFFFFF) / FLASH_PAGE_SIZE;
					EraseInitStruct.NbPages 	= 2; // 1 - 2kB
					uint32_t PageError;

					if (HAL_FLASHEx_Erase(&EraseInitStruct, &PageError) != HAL_OK)
					{
						error = HAL_FLASH_GetError ();
					}

					// Configuration
//					flash_data.d16[0] = g_joint_configuration.pole_pairs;
//					flash_data.d16[1] = g_joint_configuration.gear_ratio;
					data = (g_joint_configuration.gear_ratio << 16) | g_joint_configuration.pole_pairs;
					if (HAL_FLASH_Program(FLASH_TYPEPROGRAM_DOUBLEWORD, g_flash_address_configuration, data) != HAL_OK)
//					if (HAL_FLASH_Program(FLASH_TYPEPROGRAM_DOUBLEWORD, g_flash_address_configuration, flash_data.d64) != HAL_OK)
					{
						error = HAL_FLASH_GetError ();
					}

					data = (g_joint_configuration.reachable_electrical_rotations << 16) | g_joint_configuration.calibration_sector_size;
//					flash_data.d16[0] = g_joint_configuration.calibration_sector_size;
//					flash_data.d16[1] = g_joint_configuration.reachable_electrical_rotations;
					if (HAL_FLASH_Program(FLASH_TYPEPROGRAM_DOUBLEWORD, g_flash_address_configuration + 8, data) != HAL_OK)
					{
						error = HAL_FLASH_GetError ();
					}

					data = (g_joint_configuration.calibration_sector_size << 16) | g_joint_configuration.number_of_sectors;
					if (HAL_FLASH_Program(FLASH_TYPEPROGRAM_DOUBLEWORD, g_flash_address_configuration + 16, data) != HAL_OK)
					{
						error = HAL_FLASH_GetError ();
					}

					uint16_t * temp = (uint16_t *) &g_joint_configuration.zero_electric_position;
					data = (g_joint_configuration.zero_electric_rotation << 16) | (* temp) ;
					if (HAL_FLASH_Program(FLASH_TYPEPROGRAM_DOUBLEWORD, g_flash_address_configuration + 24, data) != HAL_OK)
					{
						error = HAL_FLASH_GetError ();
					}

					for(int i = 0; i < g_joint_configuration.number_of_sectors; i++ )
					{
						data = g_joint_configuration.calibration_table_1[i] << 16 | g_joint_configuration.calibration_table_2[i];
						if (HAL_FLASH_Program(FLASH_TYPEPROGRAM_DOUBLEWORD, g_flash_address_calibration_table + i * 8, data) != HAL_OK)
						{
							error = HAL_FLASH_GetError ();
						}
					}

					HAL_FLASH_Lock();

					FSM_Activate_State(FSM_INIT); // CALIBRATION FINISHED - GO TO INIT STATE

					HAL_TIM_Base_Start_IT(&htim6); // Enable 10 kHz timer
					break;
				}

				case FSM_START:
				{
					HAL_TIM_Base_Stop_IT(&htim6); // Enable 10 kHz timer

					// Configure CAN ID
					const uint8_t _can_start_address = 10;

					uint8_t _dip1 = (HAL_GPIO_ReadPin(GPIOB, DIP1_Pin) == GPIO_PIN_RESET) ? (0) : (8);
					uint8_t _dip2 = (HAL_GPIO_ReadPin(GPIOB, DIP2_Pin) == GPIO_PIN_RESET) ? (0) : (4);
					uint8_t _dip3 = (HAL_GPIO_ReadPin(GPIOB, DIP3_Pin) == GPIO_PIN_RESET) ? (0) : (2);
					uint8_t _dip4 = (HAL_GPIO_ReadPin(GPIOB, DIP4_Pin) == GPIO_PIN_RESET) ? (0) : (1);
					g_node_status.can_node_id = _dip2 + _dip3 + _dip4;

					// disable dip4 allow multiturn
					g_joint_configuration.working_area_constrain = _dip1;
	//	  			g_joint_configuration.ma730_exists = _dip1;

					// CAN FILTER
					g_can_filter_config.IdType = FDCAN_STANDARD_ID;
					g_can_filter_config.FilterIndex = 0;
					g_can_filter_config.FilterType = FDCAN_FILTER_DUAL;
					g_can_filter_config.FilterConfig = FDCAN_FILTER_TO_RXFIFO0;
					g_can_filter_config.FilterID1 = g_node_status.can_node_id + _can_start_address;
					g_can_filter_config.FilterID2 = 0x0AA ;

					// CAN TRANSMITION CONFIGURATION
					g_can_tx_header.Identifier = (g_node_status.can_node_id + _can_start_address) * 16;
					g_can_tx_header.IdType = FDCAN_STANDARD_ID;
					g_can_tx_header.TxFrameType = FDCAN_DATA_FRAME;
					g_can_tx_header.DataLength = FDCAN_DLC_BYTES_12;
					g_can_tx_header.ErrorStateIndicator = FDCAN_ESI_ACTIVE;
					g_can_tx_header.BitRateSwitch = FDCAN_BRS_ON;
					g_can_tx_header.FDFormat = FDCAN_FD_CAN;
					g_can_tx_header.TxEventFifoControl = FDCAN_NO_TX_EVENTS;
					g_can_tx_header.MessageMarker = 0;

					HAL_FDCAN_ConfigTxDelayCompensation(&hfdcan1, 10, 0);
					HAL_FDCAN_EnableTxDelayCompensation(&hfdcan1);

					HAL_FDCAN_ConfigFilter(&hfdcan1, &g_can_filter_config); //Initialize CAN Filter
					HAL_FDCAN_ConfigGlobalFilter(&hfdcan1, 3, 3, FDCAN_FILTER_REMOTE, FDCAN_REJECT_REMOTE);
					HAL_FDCAN_Start(&hfdcan1); //Initialize CAN Bus
					HAL_FDCAN_ActivateNotification(&hfdcan1, FDCAN_IT_RX_FIFO0_NEW_MESSAGE, 0);// Initialize CAN Bus Rx Interrupt
					HAL_FDCAN_EnableISOMode(&hfdcan1);

					// Read configuration from FLASH
					Flash_Read_Data (g_flash_address_configuration, (uint32_t *) g_calibration_config, 8);

					g_joint_configuration.calibration_table_size 			= g_calibration_config[8]; // FIXME !!!!

					if (g_joint_configuration.calibration_table_size > 0 && g_joint_configuration.calibration_table_size < 65535) {
						// Read joint configuration from FLASH
						g_joint_configuration.pole_pairs 						= g_calibration_config[0];
						g_joint_configuration.gear_ratio 						= g_calibration_config[1];
						g_joint_configuration.calibration_sector_size 			= g_calibration_config[4];
						g_joint_configuration.reachable_electrical_rotations	= g_calibration_config[5];
						g_joint_configuration.number_of_sectors 				= g_calibration_config[8];
						g_joint_configuration.zero_electric_position 			= (uint8_t) g_calibration_config[12];
						g_joint_configuration.zero_electric_rotation 			= g_calibration_config[13];

						// Read calibration table from FLASH
						//	for (int i = 0; i <= g_joint_configuration.calibration_table_size / 2 + 1; i++) {
						for (int i = 0; i <= g_joint_configuration.calibration_table_size; i++) {
							Flash_Read_Data (g_flash_address_calibration_table + i * 8, (uint32_t *) g_data, 1);
							g_joint_configuration.calibration_table_1[i]	= g_data[0] >> 16;
							g_joint_configuration.calibration_table_2[i] 	= g_data[0];
						}

						g_joint_configuration.maximum_electrical_rotations = g_joint_configuration.gear_ratio * g_joint_configuration.pole_pairs;

						g_joint_configuration.calibration_state = JOINT_CALIBRATED;

					}
					//	g_joint_configuration.hall_working_area = (6 * g_joint_configuration.pole_pairs * g_joint_configuration.gear_ratio) * 165.0 / 360.0;
					g_joint_configuration.joint_working_area_in_rad = M_PI * 165.0 / 180.0;
					// --- DLA TOMKA (BRAK KALIBRACJI WE FLASH)
					//	g_joint_configuration.pole_pairs = 14;
					//	g_joint_configuration.gear_ratio = 120;
					//	g_joint_configuration.calibration_state = JOINT_CALIBRATED;
					// --- END DLA TOMKA ---------------------

					g_node_status.security = SECURITY_DISABLED;
					g_node_status.hartbeat = HEARTBEAT_DISABLED;
					g_node_status.node_type = JOINT_BIG;

					FSM_Activate_Transition(FSM_TRANSITION_START_TO_INIT);

					HAL_TIM_Base_Start_IT(&htim6); // Enable 10 kHz timer

					break;
				}

				case FSM_TRANSITION_START_TO_INIT:
				{
					FSM_Activate_State(FSM_INIT);
					break;
				}

				case FSM_INIT:
				{
//					FSM_Activate_Transition(FSM_TRANSITION_INIT_TO_READY_TO_OPERATE);
					break;
				}

				case FSM_TRANSITION_INIT_TO_READY_TO_OPERATE:
				{
					// Check the calibration
					// If joint is not calibrated go to failure
					FSM_Activate_State(FSM_READY_TO_OPERATE);
					break;
				}

				case FSM_READY_TO_OPERATE:
				{
					motor_stop();
					break;
				}

				case FSM_TRANSITION_READY_TO_OPERATE_TO_OPERATION_ENABLE:
				{
					FSM_Activate_State(FSM_OPERATION_ENABLE);
					break;
				}

				case FSM_TRANSITION_OPERATION_ENABLE_TO_READY_TO_OPERATE:
				{
					FSM_Activate_State(FSM_READY_TO_OPERATE);
					// Stop the motor
					motor_stop();
					break;
				}

				case FSM_OPERATION_ENABLE:
				{
					g_motor_command.mode = TORQUE;
					if (g_joint_configuration.working_area_constrain)
					{
						switch (g_motor_status.current_joint_position)
						{
							case POSITION_UNDER_WORKING_AREA: // Accept only positive torque
								if (g_motor_command.goal < 0)
								{
									motor_stop();
								}
								else
								{
									motor_start(g_motor_command.mode, g_motor_command.goal);
								}
								break;

							case POSITION_IN_WORKING_AREA:
								motor_start(g_motor_command.mode, g_motor_command.goal);
								break;

							case POSITION_OVER_WORKING_AREA: // Accept only negative torque
								if (g_motor_command.goal > 0)
								{
									motor_stop();
								}
								else
								{
									motor_start(g_motor_command.mode, g_motor_command.goal);
								}
								break;
						}

					}
					else
					{
						motor_start(g_motor_command.mode, g_motor_command.goal);
					}

					break;

				}

				case FSM_TRANSITION_FAULT_TO_INIT:
				{
					MC_AcknowledgeFaultMotor1();
					g_motor_status.mc_occured_faults_motor = 0;
					FSM_Activate_State(FSM_INIT);
					break;
				}

				case FSM_TRANSITION_FAULT_REACTION_ACTIVE_TO_FAULT:
				{
					motor_stop();
					FSM_Activate_State(FSM_FAULT);
					break;
				}

				case FSM_FAULT_REACTION_ACTIVE:
				{
					FSM_Activate_Transition(FSM_TRANSITION_FAULT_REACTION_ACTIVE_TO_FAULT);
					break;
				}

				case FSM_FAULT:
				{
					break;
				}

				default:
				{
					break;
				}
			}

			// Reaction on error
			if (g_motor_status.mc_current_faults_motor > 0 || g_motor_status.mc_occured_faults_motor > 0) {
				g_motor_status.errors =  g_motor_status.errors | JOINT_MC_FAILED;
				if (FSM_Get_State() != FSM_FAULT)
				{
					FSM_Set_State(FSM_FAULT_REACTION_ACTIVE);
				}
			}
			else
			{
				g_motor_status.errors = g_motor_status.errors & (0xFF ^ JOINT_MC_FAILED);
			}

		} // end 1000 Hz

		// 100 Hz
		if (g_timer_counter % 100 == 0)
		{

			g_counter_100hz++;

		} // end 100 Hz

		// 10 Hz
		if (g_timer_counter % 1000 == 0)
		{
			g_counter_10hz++;

		} // end 10 Hz

		// 1 Hz
		if (g_timer_counter % 10000 == 0)
		{
//			// SEND HEARTBEAT BY CANBUS
//			if (g_can_heartbeat == CAN_HEARTBEAT_ENABLED)
//			{
//				const uint8_t _can_start_address = 10;
//
//				FDCAN_TxHeaderTypeDef can_tx_header; // CAN Bus Receive Header
//				uint8_t can_tx_data[8]  = {0x00, 0x00, 0x00, 0x00, 0x00, 0x00, 0x00, 0x00};
//
//				can_tx_header.Identifier = (g_node_status.can_node_id + _can_start_address);
//				can_tx_header.IdType = FDCAN_STANDARD_ID;
//				can_tx_header.TxFrameType = FDCAN_DATA_FRAME;
//				can_tx_header.DataLength = FDCAN_DLC_BYTES_6;
//				can_tx_header.ErrorStateIndicator = FDCAN_ESI_ACTIVE;
//				can_tx_header.BitRateSwitch = FDCAN_BRS_ON;
//				can_tx_header.FDFormat = FDCAN_FD_CAN;
//				can_tx_header.TxEventFifoControl = FDCAN_NO_TX_EVENTS;
//				can_tx_header.MessageMarker = 0;
//
//				if (HAL_FDCAN_AddMessageToTxFifoQ(&hfdcan1, &can_tx_header, can_tx_data) == HAL_OK)
//				{
//					g_can_tx_counter++;
//				}
//
//			}
			g_counter_1hz++;
		} // end 1 Hz

		g_timer_counter++;

		// reset counter
		if (g_timer_counter >= 10000) {
			g_timer_counter = 0;
		}
	}
}
// Current FDBK
void R3_2_GetPhaseCurrents( PWMC_Handle_t * pHdl, ab_t * Iab )
{
#if defined (__ICCARM__)
  #pragma cstat_disable = "MISRAC2012-Rule-11.3"
#endif /* __ICCARM__ */
  PWMC_R3_2_Handle_t * pHandle = ( PWMC_R3_2_Handle_t * )pHdl;
#if defined (__ICCARM__)
  #pragma cstat_restore = "MISRAC2012-Rule-11.3"
#endif /* __ICCARM__ */
  TIM_TypeDef * TIMx = pHandle->pParams_str->TIMx;

  uint8_t Sector;
  int32_t Aux;
  uint32_t ADCDataReg1;
  uint32_t ADCDataReg2;

  Sector = ( uint8_t )pHandle->_Super.Sector;
  ADCDataReg1 = *pHandle->pParams_str->ADCDataReg1[Sector];
  ADCDataReg2 = *pHandle->pParams_str->ADCDataReg2[Sector];

  /* disable ADC trigger source */
  //LL_TIM_CC_DisableChannel(TIMx, LL_TIM_CHANNEL_CH4);
  LL_TIM_SetTriggerOutput(TIMx, LL_TIM_TRGO_RESET);

  switch ( Sector )
  {
    case SECTOR_4:
    case SECTOR_5:
      /* Current on Phase C is not accessible     */
      /* Ia = PhaseAOffset - ADC converted value) */
//      Aux = ( int32_t )( pHandle->PhaseAOffset ) - ( int32_t )( ADCDataReg1 );
		Aux = (int32_t) (ADCDataReg1) - (int32_t) (pHandle->PhaseAOffset);

      /* Saturation of Ia */
      if ( Aux < -INT16_MAX )
      {
        Iab->a = -INT16_MAX;
      }
      else  if ( Aux > INT16_MAX )
      {
        Iab->a = INT16_MAX;
      }
      else
      {
        Iab->a = ( int16_t )Aux;
      }

      /* Ib = PhaseBOffset - ADC converted value) */
//      Aux = ( int32_t )( pHandle->PhaseBOffset ) - ( int32_t )( ADCDataReg2 );
      Aux = ( int32_t )( ADCDataReg2 ) - ( int32_t )( pHandle->PhaseBOffset );

      /* Saturation of Ib */
      if ( Aux < -INT16_MAX )
      {
        Iab->b = -INT16_MAX;
      }
      else  if ( Aux > INT16_MAX )
      {
        Iab->b = INT16_MAX;
      }
      else
      {
        Iab->b = ( int16_t )Aux;
      }
      break;

    case SECTOR_6:
    case SECTOR_1:
      /* Current on Phase A is not accessible     */
      /* Ib = PhaseBOffset - ADC converted value) */
//      Aux = ( int32_t )( pHandle->PhaseBOffset ) - ( int32_t )( ADCDataReg1 );
    	Aux = ( int32_t )( ADCDataReg1 ) - ( int32_t )( pHandle->PhaseBOffset );

      /* Saturation of Ib */
      if ( Aux < -INT16_MAX )
      {
        Iab->b = -INT16_MAX;
      }
      else  if ( Aux > INT16_MAX )
      {
        Iab->b = INT16_MAX;
      }
      else
      {
        Iab->b = ( int16_t )Aux;
      }

      /* Ia = -Ic -Ib */
//      Aux = ( int32_t )( ADCDataReg2 ) - ( int32_t )( pHandle->PhaseCOffset ); /* -Ic */
      Aux = ( int32_t )( pHandle->PhaseCOffset ) - ( int32_t )( ADCDataReg2 ); /* Ic reversed */
      Aux -= ( int32_t )Iab->b;             /* Ia  */

      /* Saturation of Ia */
      if ( Aux > INT16_MAX )
      {
        Iab->a = INT16_MAX;
      }
      else  if ( Aux < -INT16_MAX )
      {
        Iab->a = -INT16_MAX;
      }
      else
      {
        Iab->a = ( int16_t )Aux;
      }
      break;

    case SECTOR_2:
    case SECTOR_3:
      /* Current on Phase B is not accessible     */
      /* Ia = PhaseAOffset - ADC converted value) */
//      Aux = ( int32_t )( pHandle->PhaseAOffset ) - ( int32_t )( ADCDataReg1 );
    	Aux = ( int32_t )( ADCDataReg1 ) - ( int32_t )( pHandle->PhaseAOffset );

      /* Saturation of Ia */
      if ( Aux < -INT16_MAX )
      {
        Iab->a = -INT16_MAX;
      }
      else  if ( Aux > INT16_MAX )
      {
        Iab->a = INT16_MAX;
      }
      else
      {
        Iab->a = ( int16_t )Aux;
      }

      /* Ib = -Ic -Ia */
//      Aux = ( int32_t )( ADCDataReg2 ) - ( int32_t )( pHandle->PhaseCOffset ); /* -Ic */
      Aux = ( int32_t )( pHandle->PhaseCOffset ) - ( int32_t )( ADCDataReg2 ); /* -Ic */
      Aux -= ( int32_t )Iab->a;             /* Ib */

      /* Saturation of Ib */
      if ( Aux > INT16_MAX )
      {
        Iab->b = INT16_MAX;
      }
      else  if ( Aux < -INT16_MAX )
      {
        Iab->b = -INT16_MAX;
      }
      else
      {
        Iab->b = ( int16_t )Aux;
      }
      break;

    default:
      break;
  }

  pHandle->_Super.Ia = Iab->a;
  pHandle->_Super.Ib = Iab->b;
  pHandle->_Super.Ic = -Iab->a - Iab->b;
}

///**
//  * @brief  It set instantaneous rotor mechanical angle.
//  *         As a consequence, timer counted is computed and updated.
//  * @param  pHandle: handler of the current instance of the encoder component
//  * @param  hMecAngle new value of rotor mechanical angle (s16degrees)
//  * @retval none
//  */
//void ENC_SetMecAngle( ENCODER_Handle_t * pHandle, int16_t hMecAngle )
//{
//  TIM_TypeDef * TIMx = pHandle->TIMx;
//
//  uint16_t hAngleCounts;
//  uint16_t hMecAngleuint;
//
//  pHandle->_Super.hMecAngle = hMecAngle;
//  pHandle->_Super.hElAngle = hMecAngle * pHandle->_Super.bElToMecRatio;
//
//
//  if ( hMecAngle < 0 )
//  {
//    hMecAngle *= -1;
//    hMecAngleuint = 65535u - ( uint16_t )hMecAngle;
//  }
//  else
//  {
//    hMecAngleuint = ( uint16_t )hMecAngle;
//  }
//
//  hAngleCounts = ( uint16_t )( ( ( uint32_t )hMecAngleuint *
//                                 ( uint32_t )pHandle->PulseNumber ) / 65535u );
//
//  g_motor_status.previous_mechanical_position = g_motor_status.current_mechanical_position; // store old position
//  g_motor_status.current_mechanical_position = ENCODER_M1.PreviousCapture; // 0 ... 14336 - 1 mechanical motor rotation
//
//  if (g_motor_status.previous_mechanical_position > ENCODER_M1.PulseNumber - 4000 && g_motor_status.current_mechanical_position  < 4000)
//  {
//	g_motor_status.current_mechanical_rotation++;
//  }
//  if (g_motor_status.current_mechanical_position  > ENCODER_M1.PulseNumber - 4000 && g_motor_status.previous_mechanical_position < 4000)
//  {
//	g_motor_status.current_mechanical_rotation--;
//  }
//  g_motor_status.current_encoder_position = g_motor_status.current_mechanical_rotation * ENCODER_M1.PulseNumber + g_motor_status.current_mechanical_position;
//
//  TIMx->CNT = ( uint16_t )( hAngleCounts );
//
//}
///**
//  * @brief  IRQ implementation of the TIMER ENCODER
//  * @param  pHandle: handler of the current instance of the encoder component
//  * @param  flag used to distinguish between various IRQ sources
//  * @retval none
//  */
//void * ENC_IRQHandler( void * pHandleVoid )
//{
//  ENCODER_Handle_t * pHandle = ( ENCODER_Handle_t * ) pHandleVoid;
//
//  /*Updates the number of overflows occurred*/
//  /* the handling of overflow error is done in ENC_CalcAvrgMecSpeedUnit */
//  pHandle->TimerOverflowNb += 1u;
//
////g_motor_status.previous_mechanical_position = g_motor_status.current_mechanical_position; // store old position
////g_motor_status.current_mechanical_position = ENCODER_M1.PreviousCapture; // 0 ... 14336 - 1 mechanical motor rotation
//
//if (ENCODER_M1.PreviousCapture  < 6000)
//{
//g_motor_status.current_mechanical_rotation--;
//}
//if (ENCODER_M1.PreviousCapture  > ENCODER_M1.PulseNumber - 6000)
//{
//g_motor_status.current_mechanical_rotation++;
//}
////g_motor_status.current_encoder_position = g_motor_status.current_mechanical_rotation * ENCODER_M1.PulseNumber + g_motor_status.current_mechanical_position;
//
//  return MC_NULL;
//}

/**
* @brief  It calculates the rotor electrical and mechanical angle, on the basis
*         of the instantaneous value of the timer counter.
* @param  pHandle: handler of the current instance of the encoder component
* @retval int16_t Measured electrical angle in s16degree format.
*/
//__weak int16_t ENC_CalcAngle( ENCODER_Handle_t * pHandle )
//{
//  int32_t wtemp1;
//  int16_t elAngle;  /* s16degree format */
//  int16_t mecAngle; /* s16degree format */
//  /* PR 52926 We need to keep only the 16 LSB, bit 31 could be at 1
//   if the overflow occurs just after the entry in the High frequency task */
//  wtemp1 = ( int32_t )( LL_TIM_GetCounter( pHandle->TIMx ) & 0xffff ) *
//           ( int32_t )( pHandle->U32MAXdivPulseNumber );
//
//  /*Computes and stores the rotor mechanical angle*/
//  mecAngle = ( int16_t )( wtemp1 / 65536 );
//
//  int16_t hMecAnglePrev = pHandle->_Super.hMecAngle;
//
//  pHandle->_Super.hMecAngle = mecAngle;
//
//  /*Computes and stores the rotor electrical angle*/
//  elAngle = mecAngle * pHandle->_Super.bElToMecRatio;
//
//  pHandle->_Super.hElAngle = elAngle;
//
//  int16_t hMecSpeedDpp = mecAngle - hMecAnglePrev;
//  pHandle->_Super.wMecAngle += (int32_t)(hMecSpeedDpp);
//
//  /*Returns rotor electrical angle*/
//  return ( elAngle );
//}

uint16_t NTC_SetFaultState( NTC_Handle_t * pHandle )
{
  uint16_t hFault;

//  if ( pHandle->hAvTemp_d > pHandle->hOverTempThreshold )
//  {
//    hFault = MC_OVER_TEMP;
//  }
//  else if ( pHandle->hAvTemp_d < pHandle->hOverTempDeactThreshold )
//  {
//    hFault = MC_NO_ERROR;
//  }
//  else
//  {
    hFault = pHandle->hFaultState;
//  }
  return hFault;
}

void Flash_Read_Data(uint32_t StartPageAddress, uint32_t *RxBuf, uint16_t numberofwords)
{
	while (1)
	{
		*RxBuf = *(__IO uint32_t *)StartPageAddress;
		StartPageAddress += 4;
		RxBuf++;
		if (!(numberofwords--)) break;
	}
}

int16_t get_sector_number_from_electric_rotation_number(int16_t electric_rotation)
{
	int16_t l_sector_number 		= -1;

	l_sector_number = (electric_rotation - g_joint_configuration.calibration_sector_size + 1) / g_joint_configuration.calibration_sector_size;

	return l_sector_number;
}

int16_t get_sector_number_from_ma730(int16_t ma730_value)
{
	int16_t l_sector_number 		= -1;

	// in sector
	for (int i = 0; i < g_joint_configuration.calibration_table_size; i++)
	{
		volatile uint16_t l_lower_value 		= 0;
		volatile uint16_t l_higher_value 		= 0;
		volatile bool  	  l_sector_with_zero	= false;
		volatile bool  	  l_wynik;

		l_higher_value 	= g_joint_configuration.calibration_table_1[i];
		l_lower_value 	= g_joint_configuration.calibration_table_2[i];

		if (l_higher_value < l_lower_value)
		{
			volatile uint16_t l_tmp_value = l_higher_value;
			l_higher_value 		 = l_lower_value;
			l_lower_value 		 = l_tmp_value;
		}

		l_wynik = (l_higher_value - l_lower_value > (uint16_t) 8000);

		if (l_wynik)
		{
			l_sector_with_zero = true;
		}

		if ((l_lower_value <= ma730_value && ma730_value <= l_higher_value) && !l_sector_with_zero)
		{
			return i;
		}

		if (( (0 <= ma730_value && ma730_value <= l_lower_value) || (l_higher_value <= ma730_value && ma730_value <= 16536) ) && l_sector_with_zero)
		{
			return i;
		}

//		if ((0 <= ma730_value && ma730_value <= l_higher_value) || (l_lower_value <= ma730_value && ma730_value <= 16536))
//		{
//			return i;
//		}

		//		if (l_lower_value > l_higher_value) // cross
//		{
//			if ((0 <= ma730_value && ma730_value <= l_higher_value) || (l_lower_value <= ma730_value && ma730_value <= 16536))
//			{
//				return i;
//			}
//		}

//		if (l_lower_value <= ma730_value && ma730_value <= l_higher_value)
//		{
//			return i;
//		}
	}

	// in space between readings
	if (g_current_sector_number != -1) // FIXME WORKAROUND: place between sectors - return last
	{
		return g_current_sector_number;
	}

//	if (g_current_sector_number == -1) // FIXME WORKAROUND: place between sectors - no last sector, select farest from 0 position
//	{
//		uint16_t l_zero_sector = get_sector_number_from_electric_rotation_number(g_joint_configuration.zero_electric_rotation);
//		for (int i = 1; i < g_joint_configuration.calibration_table_size; i++)
//		{
//			uint16_t l_lower_value 	= 0;
//			uint16_t l_higher_value = 0;
//
//			l_higher_value 	= g_joint_configuration.calibration_table_1[i];
//			l_lower_value 	= g_joint_configuration.calibration_table_2[i + 1];
//
//			if (l_lower_value <= ma730_value && ma730_value <= l_higher_value)
//			{
////				return i;
//				// select farest from 0
//				if (i > l_zero_sector)
//				{
//					return g_joint_configuration.calibration_table_size;
//				}
//				else
//				{
//					return 0;
//				}
//			}
//		}
//	}

//	FSM_Transition14(); // RAISE ERROR

	return l_sector_number;
}

void motor_start(Motor_Mode_t mode, int16_t goal)
{
	g_motor_command.goal = goal;
//	g_motor_command.last_goal = goal;
	g_motor_command.mode = mode;

	switch (mode)
	{
		case TORQUE:
		{
			g_motor_command.state = MOTOR_STARTED_IN_TORQUE_MODE;
			MC_ProgramTorqueRampMotor1(g_motor_command.goal, 0);
			break;
		}

		case SPEED:
		{
			g_motor_command.state = MOTOR_STARTED_IN_SPEED_MODE;
			MC_ProgramSpeedRampMotor1(g_motor_command.goal, 0);
			break;
		}

		default:
		{
			g_motor_command.goal = 0;
//			g_motor_command.last_goal = 0;
			return;
		}
	}

	MC_StartMotor1();
}

void motor_stop()
{
//	if (g_motor_command.state != MOTOR_STOPPED)
//	{
			g_motor_command.state = MOTOR_STOPPED;
			g_motor_command.goal = 0;
//			g_motor_command.last_goal = 0;

			// clear torque readings
			for (int i = 0; i < CURRENT_TORQUE_DATA_SIZE; i++)
			{
				g_motor_status._current_torque_data[i] = 0;
			}

			g_motor_status.current_motor_torque = 0;

		    MC_StopMotor1();

//	}
}

bool motor_reach_torque_limit()
{
	if (g_motor_status.current_motor_torque > 2000 && g_motor_status.stm_state_motor == RUN) return true;

	return false;
}

bool motor_in_position(volatile int32_t position)
{
	if (abs(g_motor_status.current_encoder_position - position) < 50) return true;

	return false;
}

bool FSM_Activate_State(FSM_State_t new_state)
{
	g_fsm_status.state = new_state;
	return true;
}

bool FSM_Activate_Transition(FSM_State_t new_transition)
{
	g_fsm_status.state = new_transition;
	return true;
}

bool FSM_Set_State(FSM_State_t new_state) // FIXME running transition should block changing state to new one - add flagg transition is running
{

	switch (new_state)
	{
//#if defined CALIBRATION
//#else
		case FSM_START:
		{
			break;
		}

		case FSM_INIT:
		{
			if (FSM_Get_State() == FSM_START)
			{
				return FSM_Activate_Transition(FSM_TRANSITION_START_TO_INIT);
			}

			if (FSM_Get_State() == FSM_FAULT)
			{
				return FSM_Activate_Transition(FSM_TRANSITION_FAULT_TO_INIT);
			}
			break;
		}

		case FSM_READY_TO_OPERATE:
		{

			if (FSM_Get_State() == FSM_INIT)
			{
				return FSM_Activate_Transition(FSM_TRANSITION_INIT_TO_READY_TO_OPERATE);
			}

			if (FSM_Get_State() == FSM_OPERATION_ENABLE)
			{
				return FSM_Activate_Transition(FSM_TRANSITION_OPERATION_ENABLE_TO_READY_TO_OPERATE);
			}

			break;
		}

		case FSM_OPERATION_ENABLE:
		{
			if (FSM_Get_State() == FSM_READY_TO_OPERATE)
			{
				return FSM_Activate_Transition(FSM_TRANSITION_READY_TO_OPERATE_TO_OPERATION_ENABLE);
			}
			break;
		}

		case FSM_CALIBRATION_PHASE_1:
		{

			if (FSM_Get_State() == FSM_INIT)
			{
				return FSM_Activate_Transition(FSM_TRANSITION_INIT_TO_CALIBRATION_PHASE_1);
			}

			break;
		}

		case FSM_FAULT_REACTION_ACTIVE:
		{
			if (FSM_Get_State() != FSM_START)
			{
				return FSM_Activate_Transition(FSM_TRANSITION_FAULT_REACTION_ACTIVE_TO_FAULT);
			}
			break;
		}

		case FSM_FAULT:
		{
			if (FSM_Get_State() == FSM_READY_TO_OPERATE)
			{
				return FSM_Activate_Transition(FSM_TRANSITION_READY_TO_OPERATE_TO_OPERATION_ENABLE);
			}
			break;
		}

		default:
		{
			break;
		}
//#endif
	}

	return false;
}

FSM_State_t FSM_Get_State(void)
{
	return g_fsm_status.state;
}

//#if defined CALIBRATION
bool check_calibration_data_cw(int16_t size) {
	g_calibration_data_1_errors = 0;

	for (int i = 0; i < size; i++) {
//		if (calibration_data_1[i] == 0) g_calibration_data_1_errors++;
		if (g_joint_configuration.calibration_table_1[i] == 0) g_calibration_data_1_errors++;

	}

	if (g_calibration_data_1_errors > 0) return false;

	return true;
}

bool check_calibration_data_ccw(int16_t size) {
	g_calibration_data_2_errors = 0;

	for (int i = 0; i < size; i++) {
//		if (calibration_data_2[i] == 0) g_calibration_data_2_errors++;
		if (g_joint_configuration.calibration_table_2[i] == 0) g_calibration_data_2_errors++;
	}

	if (g_calibration_data_2_errors > 0) return false;

	return true;
}
//#else

void HAL_FDCAN_RxFifo0Callback(FDCAN_HandleTypeDef *hfdcan1, uint32_t RxFifo0ITs)
{

	if((RxFifo0ITs & FDCAN_IT_RX_FIFO0_NEW_MESSAGE) != 0)
	{

		// RETRIEVE CAN MESSAGE -------------------------------------------------------------------------
		HAL_FDCAN_GetRxMessage(hfdcan1, FDCAN_RX_FIFO0, &g_can_rx_header, g_can_rx_data);
		g_can_rx_counter++;

		// RESET SAFE TIMER -----------------------------------------------------------------------------
//		HAL_TIM_Base_Stop(&htim6);
//		TIM6->CNT = 0;
//		HAL_TIM_Base_Start_IT(&htim6);

		// UPDATE JOINT INFO ----------------------------------------------------------------------------
//		RecalculateJointState();

//		uint8_t l_can_cmd_motor_run = 0;

		if (g_can_rx_header.Identifier == 0x0AA)
		{
			int16_t goal;
			goal  = g_can_rx_data[g_node_status.can_node_id * 3] << 8;
			goal += g_can_rx_data[g_node_status.can_node_id * 3 + 1];

			g_motor_command.goal_joint_torque_in_nm = ((double) goal * 256.0) / (double) INT16_MAX; // convert from int16 to double

			uint8_t temp_new_fsm_state   = g_can_rx_data[g_node_status.can_node_id * 3 + 2];

			if (FSM_Get_State() != temp_new_fsm_state) {
				FSM_Set_State(temp_new_fsm_state);
			}

			int16_t l_current_torque = (g_motor_status.current_joint_torque_in_nm / 256.0) * (double) INT16_MAX;
			if (g_motor_command.goal < 0)
			{
				l_current_torque = -l_current_torque;
			}

			// ENCODER_NOT_ACCURATE
			if (g_motor_status.encoder_position_state != POSITION_ACCURATE)
			{
				g_motor_status.warnings = JOINT_POSITION_NOT_ACCURATE;
//				g_motor_status.warnings = g_motor_status.warnings | JOINT_POSITION_NOT_ACCURATE;

			}
			else
			{
				g_motor_status.warnings = 0;
//				g_motor_status.warnings = g_motor_status.warnings & (0xFF ^ JOINT_POSITION_NOT_ACCURATE);
			}

			int16_t l_joint_position_in_s16degree = (int16_t) (g_motor_status.current_joint_position_in_rad * (65535.0 / M_TWOPI));
			g_can_tx_data[0] 	= l_joint_position_in_s16degree >> 8;
			g_can_tx_data[1] 	= l_joint_position_in_s16degree;
			int16_t speed = g_motor_status.current_joint_speed_in_rads * (double) INT16_MAX / M_TWOPI;

			g_can_tx_data[2] 	= speed >> 8;
			g_can_tx_data[3] 	= speed;
			g_can_tx_data[4] 	= l_current_torque >> 8;
			g_can_tx_data[5] 	= l_current_torque;
			g_can_tx_data[6] 	= g_motor_status.current_temperature;
			g_can_tx_data[7] 	= FSM_Get_State();
			g_can_tx_data[8] 	= g_motor_status.mc_current_faults_motor;
			g_can_tx_data[9] 	= g_motor_status.mc_occured_faults_motor;
			g_can_tx_data[10]	= g_motor_status.errors;
			g_can_tx_data[11]	= g_motor_status.warnings;

//			 SEND FRAME VIA FD CAN -------------------------------------------------------------------------------
			if (HAL_FDCAN_AddMessageToTxFifoQ(hfdcan1, &g_can_tx_header, g_can_tx_data) == HAL_OK)
			{
				g_can_tx_counter++;
			}
		}
	}
}
//#endif

void MA730_ReadRegister(uint8_t reg_number) {
	uint16_t send_data      = 0b010 << 13 | (reg_number & (0b00011111)) << 8 ;

	uint16_t angle_value    = 0;
	uint16_t register_value = 0;

	for (uint16_t i = 0; i < 24; i++) NOP;  // wait about 150ns

	HAL_GPIO_WritePin(MA730_CS_GPIO_Port, MA730_CS_Pin, GPIO_PIN_RESET);

	for (uint16_t i = 0; i < 130; i++) NOP;  // wait about 80ns

	// SEND READ REGISTER COMMAND - RECEIVE READ ANGLE RESULT
	HAL_SPI_TransmitReceive(&hspi2, (uint8_t * ) &send_data, (uint8_t * ) &angle_value, 1, 1);

	HAL_GPIO_WritePin(MA730_CS_GPIO_Port, MA730_CS_Pin, GPIO_PIN_SET);

	for (uint16_t i = 0; i < 120; i++) NOP;  // wait about 750ns

	HAL_GPIO_WritePin(MA730_CS_GPIO_Port, MA730_CS_Pin, GPIO_PIN_RESET);

	for (uint16_t i = 0; i < 13; i++) NOP;  // wait about 80ns

	send_data      = 0x0000;

	// SEND READ ANGLE COMMAND - RECEIVE READ REGISTER RESULT
	HAL_SPI_TransmitReceive(&hspi2, (uint8_t * ) &send_data, (uint8_t * ) &register_value, 1, 1);

//	g_MA730_read_buffer = register_value >> 8;

	HAL_GPIO_WritePin(MA730_CS_GPIO_Port, MA730_CS_Pin, GPIO_PIN_SET);

	for (uint16_t i = 0; i < 120; i++) NOP;  // wait about 750ns

	g_ma730.angle = (angle_value >> 2) & 0b0011111111111111;

	register_value = register_value >> 8;
	switch (reg_number)
	{
		case 0x00:
		{
			g_ma730.z0 = (uint8_t) register_value;
			break;
		}
		case 0x01:
		{
			g_ma730.z1 = (uint8_t) register_value;
			break;
		}
		case 0x02:
		{
			g_ma730.bct = (uint8_t) register_value;
			break;
		}
		case 0x03:
		{
			g_ma730.ety = ((uint8_t) register_value & 0b00000010) >> 1;
			g_ma730.etx = ((uint8_t) register_value & 0b00000001);
			break;
		}
		case 0x04:
		{
			g_ma730.ppt0 = ((uint8_t) register_value & 0b11000000) >> 6;
			g_ma730.ilip = ((uint8_t) register_value & 0b00111100) >> 2;
			break;
		}
		case 0x05:
		{
			g_ma730.ppt1 = (uint8_t) register_value;
			break;
		}
		case 0x06:
		{
			g_ma730.mglt = ((uint8_t) register_value & 0b11100000) >> 5;
			g_ma730.mght = ((uint8_t) register_value & 0b00011100) >> 2;
			break;
		}
		case 0x09:
		{
			g_ma730.rd = (uint8_t) register_value >> 7;
			break;
		}
		case 0x1b:
		{
			g_ma730.mgl = ((uint8_t) register_value & 0b01000000) >> 6;
			g_ma730.mgh = ((uint8_t) register_value & 0b10000000) >> 7;
			break;
		}
		default:
		{
			break;
		}
	}

//	if (g_counter_1hz > 1) // wait 1 sec to analyse data
//	{
//		g_motor_status.ma730_is_running = true;
//		g_motor_status.previous_ma730_value = g_motor_status.current_ma730_value;
//		g_motor_status.current_ma730_value = (g_MA730_read_buffer >> 2) & 0b0011111111111111;
//	}

	if (g_ma730.mgl || g_ma730.mgh) // not proper magnetic field strentgh
	{
		g_motor_status.warnings |= JOINT_MA730_NOT_PROPER_MAGNETOC_FIELD;
	}
	else
	{
		g_motor_status.warnings = g_motor_status.warnings & (0xFF ^ JOINT_MA730_NOT_PROPER_MAGNETOC_FIELD);

	}

}

void MA730_ReadAngle() {
	uint16_t send_data      = 0x0000 ;

	uint16_t angle_value    = 0;

//	for (uint16_t i = 0; i < 24; i++) NOP;  // wait about 150ns

	HAL_GPIO_WritePin(MA730_CS_GPIO_Port, MA730_CS_Pin, GPIO_PIN_RESET);

//	for (uint16_t i = 0; i < 13; i++) NOP;  // wait about 80ns

	// SEND READ REGISTER COMMAND - RECEIVE READ ANGLE RESULT
	HAL_SPI_TransmitReceive(&hspi2, (uint8_t * ) &send_data, (uint8_t * ) &angle_value, 1, 1);

	HAL_GPIO_WritePin(MA730_CS_GPIO_Port, MA730_CS_Pin, GPIO_PIN_SET);

//	for (uint16_t i = 0; i < 12; i++) NOP;  // wait about 80ns

	g_ma730.angle = (angle_value >> 2) & 0b0011111111111111;

}

void MA730_WriteRegister(uint8_t reg_number, uint8_t reg_value) {
	uint16_t send_data      = 0b100 << 13 | (reg_number & (0b00011111)) << 8 | reg_value;

	uint16_t angle_value    = 0;
	uint16_t register_value = 0;

	for (uint16_t i = 0; i < 24; i++) NOP;  // wait about 150ns

	HAL_GPIO_WritePin(MA730_CS_GPIO_Port, MA730_CS_Pin, GPIO_PIN_RESET);

	for (uint16_t i = 0; i < 130; i++) NOP;  // wait about 80ns

	// SEND READ REGISTER COMMAND - RECEIVE READ ANGLE RESULT
	HAL_SPI_TransmitReceive(&hspi2, (uint8_t * ) &send_data, (uint8_t * ) &angle_value, 1, 1);

	HAL_GPIO_WritePin(MA730_CS_GPIO_Port, MA730_CS_Pin, GPIO_PIN_SET);

	HAL_Delay(20); // Wait 20 ms after write command

	HAL_GPIO_WritePin(MA730_CS_GPIO_Port, MA730_CS_Pin, GPIO_PIN_RESET);

	for (uint16_t i = 0; i < 13; i++) NOP;  // wait about 80ns

	send_data      = 0x0000;

	// SEND READ ANGLE COMMAND - RECEIVE READ REGISTER RESULT
	HAL_SPI_TransmitReceive(&hspi2, (uint8_t * ) &send_data, (uint8_t * ) &register_value, 1, 1);

	HAL_GPIO_WritePin(MA730_CS_GPIO_Port, MA730_CS_Pin, GPIO_PIN_SET);

	for (uint16_t i = 0; i < 120; i++) NOP;  // wait about 750ns

}

// Commands
// FSM XX  - set FSM STATE
// FSM     - get FSM STATE
// DIRECTION 1/0 -
// TORQUE XXXXX - set torque - 13
// SPEED XXXXX - set speed
// MULTITURN 1/0 - disabling rotation constrains
// MA730 1/0
// GETDATA

//void HAL_UART_RxCpltCallback(UART_HandleTypeDef *huart) {
//	//HAL_StatusTypeDef status;
//	uint8_t rez;
//	if (huart->Instance == USART2) {
//		rez = buff[1];
//		HAL_UART_Receive_IT(huart, &buff[1], 1);
//		huart2.gState = HAL_UART_STATE_READY;
//		//status =
//		HAL_UART_Transmit_IT(&huart2, &rez, 1);
//		//do {
//		//} while(status != HAL_OK);
//
//		cmd_buff[cmd_idx] = rez;
//		cmd_idx++;
//		if (cmd_idx >= sizeof(cmd_buff))
//			cmd_idx = 0;
//
//		if (rez == '\r') {
//			cmd_exec = parse_cmd();
//		}
//	}
//}

typedef struct {
	const uint8_t mask[9];
	const uint8_t text[9];
} one_cmd;

uint8_t parse_cmd(void)
{
	one_cmd cmds[] = { { "xxxxxxxccccddr", "xxxxxxxFSM 00r" },
                       { "xxxxxxxxxxcccr", "xxxxxxxxxxFSMr" },
                       { "xxccccccccccdr", "xxDIRECTION 0r" },
                       { "xxxxcccccccccr", "xxxxDIRECTIONr" },
                       { "xcccccccdddddr", "xTORQUE 00000r" },
                       { "xxccccccdddddr", "xxSPEED 00000r" },
                       { "xxccccccccccdr", "xxMULTITURN 0r" },
                       { "xxxxxxxxxxcccr", "xxxxxxxxxxFSMr" },
					   { "xxxxxxccccccdr", "xxxxxxMA730 0r" },
					   { "xxxxxxxcccccdr", "xxxxxxxtest 0r" }
	};

	for (uint8_t cmd = 0; cmd < sizeof(cmds) / sizeof(one_cmd); cmd++) {

//		uint8_t start_pos = (cmd_idx + BUFF_SIZE - 9) & BUFF_MASK;
//		uint16_t value = 0;
//		uint8_t rez = 0;

		for (uint8_t i = 0; i < 13; i++) {
			if (cmds[cmd].mask[i] == 'x') {
//				//dont carry
			} else if (cmds[cmd].mask[i] == 'c') {
//				//character
//				if (cmd_buff[start_pos] != cmds[cmd].text[i])
//					break;
			} else if (cmds[cmd].mask[i] == 'd') {
//				//digit
//				uint8_t digit = cmd_buff[start_pos];
//				if ((digit >= '0') || (digit <= '9')) {
//					value *= 10;
//					value += digit - '0';
//				} else
//					break;
			} else if (cmds[cmd].mask[i] == 'r') {
//				//return
//				if (cmd_buff[start_pos] != '\r')
//					break;
//				rez = 1;
			}
//			//next in cmd buffer
//			start_pos = (start_pos + 1) & BUFF_MASK;
		}
//		if (rez) {
//			cmd_value = value;
//			return cmd + 1;
//		}
	}
	return 0;
}

/* USER CODE END 4 */

void Error_Handler(void)
{
  __disable_irq();
  while (1)
  {
  }
}

/************************ (C) COPYRIGHT STMicroelectronics *****END OF FILE****/
